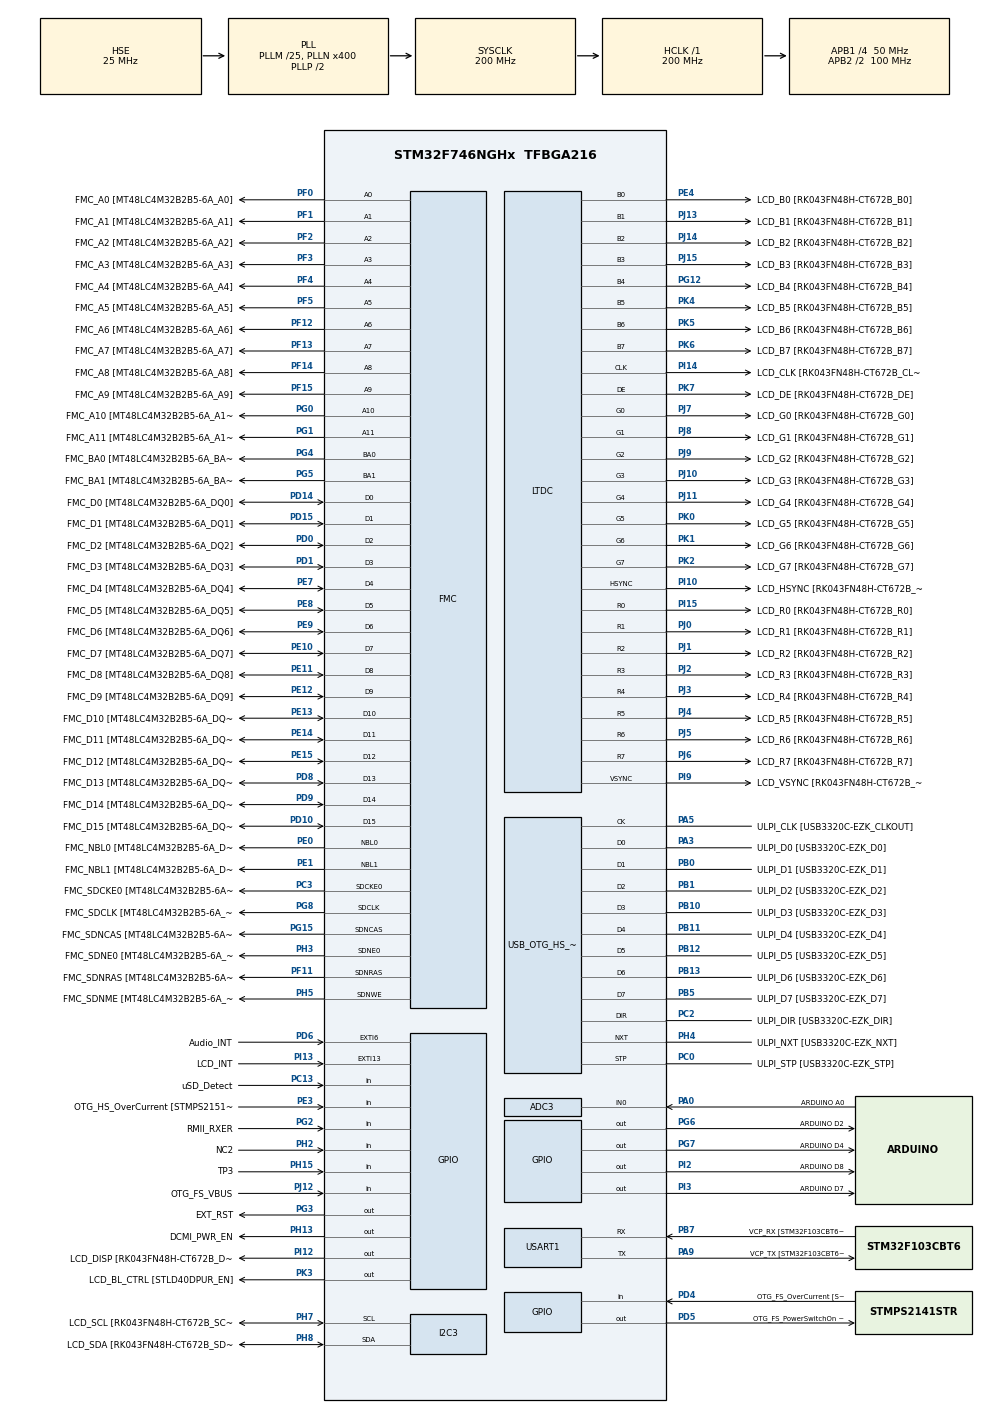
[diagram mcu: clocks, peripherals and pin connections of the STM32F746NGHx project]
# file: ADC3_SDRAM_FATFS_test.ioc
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ADC3.Channel-0\#ChannelRegularConversion=ADC_CHANNEL_0
ADC3.ClockPrescaler=ADC_CLOCK_SYNC_PCLK_DIV4
ADC3.ContinuousConvMode=DISABLE
ADC3.DMAContinuousRequests=DISABLE
ADC3.DataAlign=ADC_DATAALIGN_RIGHT
ADC3.DiscontinuousConvMode=DISABLE
ADC3.EOCSelection=ADC_EOC_SINGLE_CONV
ADC3.EnableAnalogWatchDog=false
ADC3.ExternalTrigConv=ADC_EXTERNALTRIGCONV_T2_TRGO
ADC3.ExternalTrigConvEdge=ADC_EXTERNALTRIGCONVEDGE_RISING
ADC3.InjNumberOfConversion=0
ADC3.NbrOfConversion=1
ADC3.NbrOfConversionFlag=1
ADC3.Rank-0\#ChannelRegularConversion=1
ADC3.Resolution=ADC_RESOLUTION_12B
ADC3.SamplingTime-0\#ChannelRegularConversion=ADC_SAMPLETIME_3CYCLES
ADC3.ScanConvMode=DISABLE
CORTEX_M7.ART_ACCLERATOR_ENABLE=1
CORTEX_M7.CPU_DCache=Enabled
CORTEX_M7.CPU_ICache=Enabled
CORTEX_M7.PREFETCH_ENABLE=1
Dma.ADC3.2.Direction=DMA_PERIPH_TO_MEMORY
Dma.ADC3.2.FIFOMode=DMA_FIFOMODE_DISABLE
Dma.ADC3.2.Instance=DMA2_Stream0
Dma.ADC3.2.MemDataAlignment=DMA_MDATAALIGN_HALFWORD
Dma.ADC3.2.MemInc=DMA_MINC_ENABLE
Dma.ADC3.2.Mode=DMA_NORMAL
Dma.ADC3.2.PeriphDataAlignment=DMA_PDATAALIGN_HALFWORD
Dma.ADC3.2.PeriphInc=DMA_PINC_DISABLE
Dma.ADC3.2.Priority=DMA_PRIORITY_MEDIUM
Dma.MEMTOMEM.0.Direction=DMA_MEMORY_TO_MEMORY
Dma.MEMTOMEM.0.FIFOMode=DMA_FIFOMODE_ENABLE
Dma.MEMTOMEM.0.FIFOThreshold=DMA_FIFO_THRESHOLD_FULL
Dma.MEMTOMEM.0.Instance=DMA2_Stream2
Dma.MEMTOMEM.0.MemBurst=DMA_MBURST_SINGLE
Dma.MEMTOMEM.0.MemDataAlignment=DMA_MDATAALIGN_BYTE
Dma.MEMTOMEM.0.MemInc=DMA_MINC_ENABLE
Dma.MEMTOMEM.0.Mode=DMA_NORMAL
Dma.MEMTOMEM.0.PeriphBurst=DMA_PBURST_SINGLE
Dma.MEMTOMEM.0.PeriphDataAlignment=DMA_PDATAALIGN_BYTE
Dma.MEMTOMEM.0.PeriphInc=DMA_PINC_ENABLE
Dma.MEMTOMEM.0.Priority=DMA_PRIORITY_LOW
Dma.MEMTOMEM.1.Direction=DMA_MEMORY_TO_MEMORY
Dma.MEMTOMEM.1.FIFOMode=DMA_FIFOMODE_ENABLE
Dma.MEMTOMEM.1.FIFOThreshold=DMA_FIFO_THRESHOLD_FULL
Dma.MEMTOMEM.1.Instance=DMA2_Stream1
Dma.MEMTOMEM.1.MemBurst=DMA_MBURST_SINGLE
Dma.MEMTOMEM.1.MemDataAlignment=DMA_MDATAALIGN_BYTE
Dma.MEMTOMEM.1.MemInc=DMA_MINC_ENABLE
Dma.MEMTOMEM.1.Mode=DMA_NORMAL
Dma.MEMTOMEM.1.PeriphBurst=DMA_PBURST_SINGLE
Dma.MEMTOMEM.1.PeriphDataAlignment=DMA_PDATAALIGN_BYTE
Dma.MEMTOMEM.1.PeriphInc=DMA_PINC_ENABLE
Dma.MEMTOMEM.1.Priority=DMA_PRIORITY_LOW
Dma.Request0=MEMTOMEM
Dma.Request1=MEMTOMEM
Dma.Request2=ADC3
FMC.CASLatency1=FMC_SDRAM_CAS_LATENCY_2
FMC.ExitSelfRefreshDelay1=7
FMC.LoadToActiveDelay1=2
FMC.RCDDelay1=2
FMC.RPDelay1=2
FMC.RPDelay2=2
FMC.ReadBurst1=FMC_SDRAM_RBURST_ENABLE
FMC.ReadBurst2=FMC_SDRAM_RBURST_ENABLE
FMC.RowCycleDelay1=6
FMC.RowCycleDelay2=6
FMC.SDClockPeriod1=FMC_SDRAM_CLOCK_PERIOD_2
FMC.SDClockPeriod2=FMC_SDRAM_CLOCK_PERIOD_2
FMC.SelfRefreshTime1=4
FMC.WriteRecoveryTime1=2
FREERTOS.Tasks01=defaultTask,0,128,StartDefaultTask,Default,NULL
I2C3.OwnAddress=112
I2C3.Timing=0x00C0EAFF
LTDC.ActiveH=272
LTDC.ActiveW=480
LTDC.Alpha_L0=255
LTDC.BlendingFactor1_L0=LTDC_BLENDING_FACTOR1_CA
LTDC.BlendingFactor2_L0=LTDC_BLENDING_FACTOR2_CA
LTDC.HBP=13
LTDC.HFP=32
LTDC.HSync=41
LTDC.Layers=0
LTDC.PCPolarity=LTDC_PCPOLARITY_IPC
LTDC.VBP=2
LTDC.VFP=2
LTDC.VSync=10
LTDC.WindowX1_L0=480
LTDC.WindowY1_L0=272
Mcu.Family=STM32F7
Mcu.Name=STM32F746NGHx
Mcu.Package=TFBGA216
NVIC.DMA2_Stream0_IRQn=true\:5\:0\:false\:false\:true\:true\:false
NVIC.OTG_HS_IRQn=true\:5\:0\:false\:false\:true\:true\:false
NVIC.PriorityGroup=NVIC_PRIORITYGROUP_4
NVIC.TIM1_UP_TIM10_IRQn=true\:0\:0\:false\:false\:true\:false\:false
NVIC.TimeBase=TIM1_UP_TIM10_IRQn
NVIC.TimeBaseIP=TIM1
PA0/WKUP.GPIO_Label=ARDUINO A0
PA0/WKUP.GPIO_Mode=GPIO_MODE_ANALOG
PA0/WKUP.GPIO_PuPd=GPIO_NOPULL
PA0/WKUP.Signal=ADCx_IN0
PA1.GPIO_Label=RMII_REF_CLK [LAN8742A-CZ-TR_REFCLK0]
PA1.Signal=ETH_REF_CLK
PA10.GPIO_Label=OTG_FS_ID
PA10.Signal=USB_OTG_FS_ID
PA11.GPIO_Label=OTG_FS_N
PA11.Signal=USB_OTG_FS_DM
PA12.GPIO_Label=OTG_FS_P
PA12.Signal=USB_OTG_FS_DP
PA13.GPIO_Label=SWDIO
PA13.Mode=Serial_Wire
PA13.Signal=SYS_JTMS-SWDIO
PA14.GPIO_Label=SWCLK
PA14.Mode=Serial_Wire
PA14.Signal=SYS_JTCK-SWCLK
PA2.GPIO_Label=RMII_MDIO [LAN8742A-CZ-TR_MDIO]
PA2.Signal=ETH_MDIO
PA3.GPIO_Label=ULPI_D0 [USB3320C-EZK_D0]
PA3.Mode=Host_HS
PA3.Signal=USB_OTG_HS_ULPI_D0
PA4.GPIO_Label=DCMI_HSYNC
PA4.Signal=DCMI_HSYNC
PA5.GPIO_Label=ULPI_CLK [USB3320C-EZK_CLKOUT]
PA5.Mode=Host_HS
PA5.Signal=USB_OTG_HS_ULPI_CK
PA6.Signal=DCMI_PIXCLK
PA7.GPIO_Label=RMII_CRS_DV [LAN8742A-CZ-TR_CRS_DV]
PA7.Signal=ETH_CRS_DV
PA8.GPIO_Label=ARDUINO PWM/D5
PA8.GPIO_ModeDefaultPP=GPIO_MODE_AF_PP
PA8.GPIO_PuPd=GPIO_NOPULL
PA8.GPIO_Speed=GPIO_SPEED_FREQ_LOW
PA8.Signal=S_TIM1_CH1
PA9.GPIO_Label=VCP_TX [STM32F103CBT6_PA3]
PA9.GPIO_Mode=GPIO_MODE_AF_PP
PA9.GPIO_PuPd=GPIO_NOPULL
PA9.GPIO_Speed=GPIO_SPEED_FREQ_LOW
PA9.Mode=Asynchronous
PA9.Signal=USART1_TX
PB0.GPIO_Label=ULPI_D1 [USB3320C-EZK_D1]
PB0.Mode=Host_HS
PB0.Signal=USB_OTG_HS_ULPI_D1
PB1.GPIO_Label=ULPI_D2 [USB3320C-EZK_D2]
PB1.Mode=Host_HS
PB1.Signal=USB_OTG_HS_ULPI_D2
PB10.GPIO_Label=ULPI_D3 [USB3320C-EZK_D3]
PB10.Mode=Host_HS
PB10.Signal=USB_OTG_HS_ULPI_D3
PB11.GPIO_Label=ULPI_D4 [USB3320C-EZK_D4]
PB11.Mode=Host_HS
PB11.Signal=USB_OTG_HS_ULPI_D4
PB12.GPIO_Label=ULPI_D5 [USB3320C-EZK_D5]
PB12.Mode=Host_HS
PB12.Signal=USB_OTG_HS_ULPI_D5
PB13.GPIO_Label=ULPI_D6 [USB3320C-EZK_D6]
PB13.Mode=Host_HS
PB13.Signal=USB_OTG_HS_ULPI_D6
PB14.GPIO_Label=ARDUINO MISO/D12
PB14.GPIO_Mode=GPIO_MODE_AF_PP
PB14.GPIO_PuPd=GPIO_NOPULL
PB14.GPIO_Speed=GPIO_SPEED_FREQ_LOW
PB14.Signal=SPI2_MISO
PB15.GPIO_Label=ARDUINO MOSI/PWM/D11
PB15.GPIO_Mode=GPIO_MODE_AF_PP
PB15.GPIO_PuPd=GPIO_NOPULL
PB15.GPIO_Speed=GPIO_SPEED_FREQ_LOW
PB15.Signal=SPI2_MOSI
PB2.Signal=QUADSPI_CLK
PB3.GPIO_Label=SWO
PB3.Signal=SYS_JTDO-SWO
PB4.GPIO_Label=ARDUINO PWM/D3
PB4.GPIO_ModeDefaultPP=GPIO_MODE_AF_PP
PB4.GPIO_PuPd=GPIO_NOPULL
PB4.GPIO_Speed=GPIO_SPEED_FREQ_LOW
PB4.Signal=S_TIM3_CH1
PB5.GPIO_Label=ULPI_D7 [USB3320C-EZK_D7]
PB5.Mode=Host_HS
PB5.Signal=USB_OTG_HS_ULPI_D7
PB6.GPIO_Label=QSPI_NCS [N25Q128A13EF840E_S]
PB6.Signal=QUADSPI_BK1_NCS
PB7.GPIO_Label=VCP_RX [STM32F103CBT6_PA2]
PB7.GPIO_Mode=GPIO_MODE_AF_PP
PB7.GPIO_PuPd=GPIO_NOPULL
PB7.GPIO_Speed=GPIO_SPEED_FREQ_LOW
PB7.Mode=Asynchronous
PB7.Signal=USART1_RX
PB8.GPIO_Label=ARDUINO SCL/D15
PB8.GPIO_Mode=GPIO_MODE_AF_OD
PB8.GPIO_PuPd=GPIO_NOPULL
PB8.GPIO_Speed=GPIO_SPEED_FREQ_LOW
PB8.Signal=I2C1_SCL
PB9.GPIO_Label=ARDUINO SDA/D14
PB9.GPIO_Mode=GPIO_MODE_AF_OD
PB9.GPIO_PuPd=GPIO_NOPULL
PB9.GPIO_Speed=GPIO_SPEED_FREQ_LOW
PB9.Signal=I2C1_SDA
PC0.GPIO_Label=ULPI_STP [USB3320C-EZK_STP]
PC0.Mode=Host_HS
PC0.Signal=USB_OTG_HS_ULPI_STP
PC1.GPIO_Label=RMII_MDC [LAN8742A-CZ-TR_MDC]
PC1.Signal=ETH_MDC
PC10.GPIO_Label=SDMMC_D2
PC10.Signal=SDMMC1_D2
PC11.GPIO_Label=SDMMC_D3
PC11.Signal=SDMMC1_D3
PC12.GPIO_Label=SDMMC_CK
PC12.Signal=SDMMC1_CK
PC13.GPIO_Label=uSD_Detect
PC13.Signal=GPIO_Input
PC14/OSC32_IN.GPIO_Label=RCC_OSC32_IN
PC14/OSC32_IN.Mode=LSE-External-Oscillator
PC14/OSC32_IN.Signal=RCC_OSC32_IN
PC15/OSC32_OUT.GPIO_Label=RCC_OSC32_OUT
PC15/OSC32_OUT.Mode=LSE-External-Oscillator
PC15/OSC32_OUT.Signal=RCC_OSC32_OUT
PC2.GPIO_Label=ULPI_DIR [USB3320C-EZK_DIR]
PC2.Mode=Host_HS
PC2.Signal=USB_OTG_HS_ULPI_DIR
PC3.GPIO_Label=FMC_SDCKE0 [MT48LC4M32B2B5-6A_CKE]
PC3.Mode=SdramChipSelect1_1
PC3.Signal=FMC_SDCKE0
PC4.GPIO_Label=RMII_RXD0 [LAN8742A-CZ-TR_RXD0]
PC4.Signal=ETH_RXD0
PC5.GPIO_Label=RMII_RXD1 [LAN8742A-CZ-TR_RXD1]
PC5.Signal=ETH_RXD1
PC6.GPIO_Label=ARDUINO TX/D1
PC6.Signal=USART6_TX
PC7.GPIO_Label=ARDUINO RX/D0
PC7.Signal=USART6_RX
PC8.Signal=SDMMC1_D0
PC9.Signal=SDMMC1_D1
PD0.GPIO_Label=FMC_D2 [MT48LC4M32B2B5-6A_DQ2]
PD0.Signal=FMC_D2_DA2
PD1.GPIO_Label=FMC_D3 [MT48LC4M32B2B5-6A_DQ3]
PD1.Signal=FMC_D3_DA3
PD10.GPIO_Label=FMC_D15 [MT48LC4M32B2B5-6A_DQ15]
PD10.Signal=FMC_D15_DA15
PD11.GPIO_Label=QSPI_D0 [N25Q128A13EF840E_DQ0]
PD11.Signal=QUADSPI_BK1_IO0
PD12.GPIO_Label=QSPI_D1 [N25Q128A13EF840E_DQ1]
PD12.Signal=QUADSPI_BK1_IO1
PD13.GPIO_Label=QSPI_D3 [N25Q128A13EF840E_DQ3]
PD13.Signal=QUADSPI_BK1_IO3
PD14.GPIO_Label=FMC_D0 [MT48LC4M32B2B5-6A_DQ0]
PD14.Signal=FMC_D0_DA0
PD15.GPIO_Label=FMC_D1 [MT48LC4M32B2B5-6A_DQ1]
PD15.Signal=FMC_D1_DA1
PD2.GPIO_Label=SDMMC_D0
PD2.Signal=SDMMC1_CMD
PD3.GPIO_Label=DCMI_D5
PD3.Signal=DCMI_D5
PD4.GPIO_Label=OTG_FS_OverCurrent [STMPS2141STR_Fault]
PD4.Signal=GPIO_Input
PD5.GPIO_Label=OTG_FS_PowerSwitchOn [STMPS2141STR_EN]
PD5.PinState=GPIO_PIN_SET
PD5.Signal=GPIO_Output
PD6.GPIO_Label=Audio_INT
PD6.GPIO_ModeDefaultEXTI=GPIO_MODE_EVT_RISING
PD6.Signal=GPXTI6
PD7.GPIO_Label=SPDIF_RX0 [74LVC1G04SE_4]
PD7.Signal=SPDIFRX_IN0
PD8.GPIO_Label=FMC_D13 [MT48LC4M32B2B5-6A_DQ13]
PD8.Signal=FMC_D13_DA13
PD9.GPIO_Label=FMC_D14 [MT48LC4M32B2B5-6A_DQ14]
PD9.Signal=FMC_D14_DA14
PE0.GPIO_Label=FMC_NBL0 [MT48LC4M32B2B5-6A_DQM0]
PE0.Signal=FMC_NBL0
PE1.GPIO_Label=FMC_NBL1 [MT48LC4M32B2B5-6A_DQM1]
PE1.Signal=FMC_NBL1
PE10.GPIO_Label=FMC_D7 [MT48LC4M32B2B5-6A_DQ7]
PE10.Signal=FMC_D7_DA7
PE11.GPIO_Label=FMC_D8 [MT48LC4M32B2B5-6A_DQ8]
PE11.Signal=FMC_D8_DA8
PE12.GPIO_Label=FMC_D9 [MT48LC4M32B2B5-6A_DQ9]
PE12.Signal=FMC_D9_DA9
PE13.GPIO_Label=FMC_D10 [MT48LC4M32B2B5-6A_DQ10]
PE13.Signal=FMC_D10_DA10
PE14.GPIO_Label=FMC_D11 [MT48LC4M32B2B5-6A_DQ11]
PE14.Signal=FMC_D11_DA11
PE15.GPIO_Label=FMC_D12 [MT48LC4M32B2B5-6A_DQ12]
PE15.Signal=FMC_D12_DA12
PE2.GPIO_Label=QSPI_D2 [N25Q128A13EF840E_DQ2]
PE2.Signal=QUADSPI_BK1_IO2
PE3.GPIO_Label=OTG_HS_OverCurrent [STMPS2151STR_FAULT]
PE3.Signal=GPIO_Input
PE4.GPIO_Label=LCD_B0 [RK043FN48H-CT672B_B0]
PE4.Mode=RGB888
PE4.Signal=LTDC_B0
PE5.GPIO_Label=DCMI_D6
PE5.Signal=DCMI_D6
PE6.GPIO_Label=DCMI_D7
PE6.Signal=DCMI_D7
PE7.GPIO_Label=FMC_D4 [MT48LC4M32B2B5-6A_DQ4]
PE7.Signal=FMC_D4_DA4
PE8.GPIO_Label=FMC_D5 [MT48LC4M32B2B5-6A_DQ5]
PE8.Signal=FMC_D5_DA5
PE9.GPIO_Label=FMC_D6 [MT48LC4M32B2B5-6A_DQ6]
PE9.Signal=FMC_D6_DA6
PF0.GPIO_Label=FMC_A0 [MT48LC4M32B2B5-6A_A0]
PF0.Signal=FMC_A0
PF1.GPIO_Label=FMC_A1 [MT48LC4M32B2B5-6A_A1]
PF1.Signal=FMC_A1
PF10.GPIO_Label=ARDUINO A1
PF10.GPIO_Mode=GPIO_MODE_ANALOG
PF10.GPIO_PuPd=GPIO_NOPULL
PF10.Signal=ADC3_IN8
PF11.GPIO_Label=FMC_SDNRAS [MT48LC4M32B2B5-6A_RAS]
PF11.Signal=FMC_SDNRAS
PF12.GPIO_Label=FMC_A6 [MT48LC4M32B2B5-6A_A6]
PF12.Signal=FMC_A6
PF13.GPIO_Label=FMC_A7 [MT48LC4M32B2B5-6A_A7]
PF13.Signal=FMC_A7
PF14.GPIO_Label=FMC_A8 [MT48LC4M32B2B5-6A_A8]
PF14.Signal=FMC_A8
PF15.GPIO_Label=FMC_A9 [MT48LC4M32B2B5-6A_A9]
PF15.Signal=FMC_A9
PF2.GPIO_Label=FMC_A2 [MT48LC4M32B2B5-6A_A2]
PF2.Signal=FMC_A2
PF3.GPIO_Label=FMC_A3 [MT48LC4M32B2B5-6A_A3]
PF3.Signal=FMC_A3
PF4.GPIO_Label=FMC_A4 [MT48LC4M32B2B5-6A_A4]
PF4.Signal=FMC_A4
PF5.GPIO_Label=FMC_A5 [MT48LC4M32B2B5-6A_A5]
PF5.Signal=FMC_A5
PF6.GPIO_Label=ARDUINO A5
PF6.GPIO_Mode=GPIO_MODE_ANALOG
PF6.GPIO_PuPd=GPIO_NOPULL
PF6.Signal=ADC3_IN4
PF7.GPIO_Label=ARDUINO A4
PF7.GPIO_Mode=GPIO_MODE_ANALOG
PF7.GPIO_PuPd=GPIO_NOPULL
PF7.Signal=ADC3_IN5
PF8.GPIO_Label=ARDUINO A3
PF8.GPIO_Mode=GPIO_MODE_ANALOG
PF8.GPIO_PuPd=GPIO_NOPULL
PF8.Signal=ADC3_IN6
PF9.GPIO_Label=ARDUINO A2
PF9.GPIO_Mode=GPIO_MODE_ANALOG
PF9.GPIO_PuPd=GPIO_NOPULL
PF9.Signal=ADC3_IN7
PG0.GPIO_Label=FMC_A10 [MT48LC4M32B2B5-6A_A10]
PG0.Signal=FMC_A10
PG1.GPIO_Label=FMC_A11 [MT48LC4M32B2B5-6A_A11]
PG1.Signal=FMC_A11
PG10.GPIO_Label=SAI2_SDB [WM8994ECS/R_ADCDAT1]
PG10.Signal=SAI2_SD_B
PG11.GPIO_Label=RMII_TX_EN [LAN8742A-CZ-TR_TXEN]
PG11.Signal=ETH_TX_EN
PG12.GPIO_Label=LCD_B4 [RK043FN48H-CT672B_B4]
PG12.Mode=RGB888
PG12.Signal=LTDC_B4
PG13.GPIO_Label=RMII_TXD0 [LAN8742A-CZ-TR_TXD0]
PG13.Signal=ETH_TXD0
PG14.GPIO_Label=RMII_TXD1 [LAN8742A-CZ-TR_TXD1]
PG14.Signal=ETH_TXD1
PG15.GPIO_Label=FMC_SDNCAS [MT48LC4M32B2B5-6A_CAS]
PG15.Signal=FMC_SDNCAS
PG2.GPIO_Label=RMII_RXER
PG2.Signal=GPIO_Input
PG3.GPIO_Label=EXT_RST
PG3.Signal=GPIO_Output
PG4.GPIO_Label=FMC_BA0 [MT48LC4M32B2B5-6A_BA0]
PG4.Signal=FMC_A14_BA0
PG5.GPIO_Label=FMC_BA1 [MT48LC4M32B2B5-6A_BA1]
PG5.Signal=FMC_A15_BA1
PG6.GPIO_Label=ARDUINO D2
PG6.Signal=GPIO_Output
PG7.GPIO_Label=ARDUINO D4
PG7.Signal=GPIO_Output
PG8.GPIO_Label=FMC_SDCLK [MT48LC4M32B2B5-6A_CLK]
PG8.Signal=FMC_SDCLK
PG9.GPIO_Label=DCMI_VSYNC
PG9.Signal=DCMI_VSYNC
PH0/OSC_IN.GPIO_Label=OSC_25M [NZ2520SB-25.00M_OUT]
PH0/OSC_IN.Mode=HSE-External-Oscillator
PH0/OSC_IN.Signal=RCC_OSC_IN
PH1/OSC_OUT.Mode=HSE-External-Oscillator
PH1/OSC_OUT.Signal=RCC_OSC_OUT
PH10.GPIO_Label=DCMI_D1
PH10.Signal=DCMI_D1
PH11.GPIO_Label=DCMI_D2
PH11.Signal=DCMI_D2
PH12.GPIO_Label=DCMI_D3
PH12.Signal=DCMI_D3
PH13.GPIO_Label=DCMI_PWR_EN
PH13.Signal=GPIO_Output
PH14.GPIO_Label=DCMI_D4
PH14.Signal=DCMI_D4
PH15.GPIO_Label=TP3
PH15.Signal=GPIO_Input
PH2.GPIO_Label=NC2
PH2.Signal=GPIO_Input
PH3.GPIO_Label=FMC_SDNE0 [MT48LC4M32B2B5-6A_CS]
PH3.Mode=SdramChipSelect1_1
PH3.Signal=FMC_SDNE0
PH4.GPIO_Label=ULPI_NXT [USB3320C-EZK_NXT]
PH4.Mode=Host_HS
PH4.Signal=USB_OTG_HS_ULPI_NXT
PH5.GPIO_Label=FMC_SDNME [MT48LC4M32B2B5-6A_WE]
PH5.Signal=FMC_SDNWE
PH6.GPIO_Label=ARDUINO PWM/D6
PH6.Signal=S_TIM12_CH1
PH7.GPIO_Label=LCD_SCL [RK043FN48H-CT672B_SCL]
PH7.Mode=I2C
PH7.Signal=I2C3_SCL
PH8.GPIO_Label=LCD_SDA [RK043FN48H-CT672B_SDA]
PH8.Mode=I2C
PH8.Signal=I2C3_SDA
PH9.GPIO_Label=DCMI_D0
PH9.Signal=DCMI_D0
PI0.GPIO_Label=ARDUINO PWM/CS/D10
PI0.GPIO_ModeDefaultPP=GPIO_MODE_AF_PP
PI0.GPIO_PuPd=GPIO_NOPULL
PI0.GPIO_Speed=GPIO_SPEED_FREQ_LOW
PI0.Signal=S_TIM5_CH4
PI1.GPIO_Label=ARDUINO SCK/D13
PI1.GPIO_Mode=GPIO_MODE_AF_PP
PI1.GPIO_PuPd=GPIO_NOPULL
PI1.GPIO_Speed=GPIO_SPEED_FREQ_LOW
PI1.Signal=SPI2_SCK
PI10.GPIO_Label=LCD_HSYNC [RK043FN48H-CT672B_HSYNC]
PI10.Mode=RGB888
PI10.Signal=LTDC_HSYNC
PI11.Mode=SYS_WakeUp5
PI11.Signal=SYS_WKUP6
PI12.GPIO_Label=LCD_DISP [RK043FN48H-CT672B_DISP] 
PI12.Signal=GPIO_Output
PI13.GPIO_Label=LCD_INT
PI13.GPIO_ModeDefaultEXTI=GPIO_MODE_EVT_RISING
PI13.Signal=GPXTI13
PI14.GPIO_Label=LCD_CLK [RK043FN48H-CT672B_CLK]
PI14.Mode=RGB888
PI14.Signal=LTDC_CLK
PI15.GPIO_Label=LCD_R0 [RK043FN48H-CT672B_R0]
PI15.Mode=RGB888
PI15.Signal=LTDC_R0
PI2.GPIO_Label=ARDUINO D8
PI2.Signal=GPIO_Output
PI3.GPIO_Label=ARDUINO D7
PI3.Signal=GPIO_Output
PI4.GPIO_Label=SAI2_MCLKA [WM8994ECS/R_MCLK1]
PI4.Signal=SAI2_MCLK_A
PI5.GPIO_Label=SAI2_SCKA [WM8994ECS/R_BCLK1]
PI5.Signal=SAI2_SCK_A
PI6.GPIO_Label=SAI2_SDA [WM8994ECS/R_DACDAT1]
PI6.Signal=SAI2_SD_A
PI7.GPIO_Label=SAI2_FSA [WM8994ECS/R_LRCLK1]
PI7.Signal=SAI2_FS_A
PI8.GPIO_Label=NC1 [TP2]
PI8.Signal=RTC_TS
PI9.GPIO_Label=LCD_VSYNC [RK043FN48H-CT672B_VSYNC]
PI9.Mode=RGB888
PI9.Signal=LTDC_VSYNC
PJ0.GPIO_Label=LCD_R1 [RK043FN48H-CT672B_R1]
PJ0.Mode=RGB888
PJ0.Signal=LTDC_R1
PJ1.GPIO_Label=LCD_R2 [RK043FN48H-CT672B_R2]
PJ1.Mode=RGB888
PJ1.Signal=LTDC_R2
PJ10.GPIO_Label=LCD_G3 [RK043FN48H-CT672B_G3]
PJ10.Mode=RGB888
PJ10.Signal=LTDC_G3
PJ11.GPIO_Label=LCD_G4 [RK043FN48H-CT672B_G4]
PJ11.Mode=RGB888
PJ11.Signal=LTDC_G4
PJ12.GPIO_Label=OTG_FS_VBUS
PJ12.Signal=GPIO_Input
PJ13.GPIO_Label=LCD_B1 [RK043FN48H-CT672B_B1]
PJ13.Mode=RGB888
PJ13.Signal=LTDC_B1
PJ14.GPIO_Label=LCD_B2 [RK043FN48H-CT672B_B2]
PJ14.Mode=RGB888
PJ14.Signal=LTDC_B2
PJ15.GPIO_Label=LCD_B3 [RK043FN48H-CT672B_B3]
PJ15.Mode=RGB888
PJ15.Signal=LTDC_B3
PJ2.GPIO_Label=LCD_R3 [RK043FN48H-CT672B_R3]
PJ2.Mode=RGB888
PJ2.Signal=LTDC_R3
PJ3.GPIO_Label=LCD_R4 [RK043FN48H-CT672B_R4]
PJ3.Mode=RGB888
PJ3.Signal=LTDC_R4
PJ4.GPIO_Label=LCD_R5 [RK043FN48H-CT672B_R5]
PJ4.Mode=RGB888
PJ4.Signal=LTDC_R5
PJ5.GPIO_Label=LCD_R6 [RK043FN48H-CT672B_R6]
PJ5.Mode=RGB888
PJ5.Signal=LTDC_R6
PJ6.GPIO_Label=LCD_R7 [RK043FN48H-CT672B_R7]
PJ6.Mode=RGB888
PJ6.Signal=LTDC_R7
PJ7.GPIO_Label=LCD_G0 [RK043FN48H-CT672B_G0]
PJ7.Mode=RGB888
PJ7.Signal=LTDC_G0
PJ8.GPIO_Label=LCD_G1 [RK043FN48H-CT672B_G1]
PJ8.Mode=RGB888
PJ8.Signal=LTDC_G1
PJ9.GPIO_Label=LCD_G2 [RK043FN48H-CT672B_G2]
PJ9.Mode=RGB888
PJ9.Signal=LTDC_G2
PK0.GPIO_Label=LCD_G5 [RK043FN48H-CT672B_G5]
PK0.Mode=RGB888
PK0.Signal=LTDC_G5
PK1.GPIO_Label=LCD_G6 [RK043FN48H-CT672B_G6]
PK1.Mode=RGB888
PK1.Signal=LTDC_G6
PK2.GPIO_Label=LCD_G7 [RK043FN48H-CT672B_G7]
PK2.Mode=RGB888
PK2.Signal=LTDC_G7
PK3.GPIO_Label=LCD_BL_CTRL [STLD40DPUR_EN]
PK3.Signal=GPIO_Output
PK4.GPIO_Label=LCD_B5 [RK043FN48H-CT672B_B5]
PK4.Mode=RGB888
PK4.Signal=LTDC_B5
PK5.GPIO_Label=LCD_B6 [RK043FN48H-CT672B_B6]
PK5.Mode=RGB888
PK5.Signal=LTDC_B6
PK6.GPIO_Label=LCD_B7 [RK043FN48H-CT672B_B7]
PK6.Mode=RGB888
PK6.Signal=LTDC_B7
PK7.GPIO_Label=LCD_DE [RK043FN48H-CT672B_DE]
PK7.Mode=RGB888
PK7.Signal=LTDC_DE
ProjectManager.HeapSize=0x200
ProjectManager.StackSize=0x400
ProjectManager.TargetToolchain=TrueSTUDIO
RCC.AHBFreq_Value=200000000
RCC.APB1CLKDivider=RCC_HCLK_DIV4
RCC.APB1Freq_Value=50000000
RCC.APB1TimFreq_Value=100000000
RCC.APB2CLKDivider=RCC_HCLK_DIV2
RCC.APB2Freq_Value=100000000
RCC.APB2TimFreq_Value=200000000
RCC.CortexFreq_Value=200000000
RCC.HCLKFreq_Value=200000000
RCC.HSE_VALUE=25000000
RCC.HSI_VALUE=16000000
RCC.PLLI2SN=100
RCC.PLLM=25
RCC.PLLN=400
RCC.PLLQ=9
RCC.PLLSAIN=190
RCC.PLLSAIR=5
RCC.PLLSAIRDiv=RCC_PLLSAIDIVR_4
RCC.PLLSourceVirtual=RCC_PLLSOURCE_HSE
RCC.SYSCLKFreq_VALUE=200000000
RCC.SYSCLKSource=RCC_SYSCLKSOURCE_PLLCLK
RCC.USBFreq_Value=44444444.44444445
RCC.VCOOutputFreq_Value=400000000
SH.ADCx_IN0.0=ADC3_IN0,IN0
SH.FMC_A0.0=FMC_A0,12b-sda1
SH.FMC_A1.0=FMC_A1,12b-sda1
SH.FMC_A10.0=FMC_A10,12b-sda1
SH.FMC_A11.0=FMC_A11,12b-sda1
SH.FMC_A14_BA0.0=FMC_BA0,FourSdramBanks1
SH.FMC_A15_BA1.0=FMC_BA1,FourSdramBanks1
SH.FMC_A2.0=FMC_A2,12b-sda1
SH.FMC_A3.0=FMC_A3,12b-sda1
SH.FMC_A4.0=FMC_A4,12b-sda1
SH.FMC_A5.0=FMC_A5,12b-sda1
SH.FMC_A6.0=FMC_A6,12b-sda1
SH.FMC_A7.0=FMC_A7,12b-sda1
SH.FMC_A8.0=FMC_A8,12b-sda1
SH.FMC_A9.0=FMC_A9,12b-sda1
SH.FMC_D0_DA0.0=FMC_D0,sd-16b-d1
SH.FMC_D10_DA10.0=FMC_D10,sd-16b-d1
SH.FMC_D11_DA11.0=FMC_D11,sd-16b-d1
SH.FMC_D12_DA12.0=FMC_D12,sd-16b-d1
SH.FMC_D13_DA13.0=FMC_D13,sd-16b-d1
SH.FMC_D14_DA14.0=FMC_D14,sd-16b-d1
SH.FMC_D15_DA15.0=FMC_D15,sd-16b-d1
SH.FMC_D1_DA1.0=FMC_D1,sd-16b-d1
SH.FMC_D2_DA2.0=FMC_D2,sd-16b-d1
SH.FMC_D3_DA3.0=FMC_D3,sd-16b-d1
SH.FMC_D4_DA4.0=FMC_D4,sd-16b-d1
SH.FMC_D5_DA5.0=FMC_D5,sd-16b-d1
SH.FMC_D6_DA6.0=FMC_D6,sd-16b-d1
SH.FMC_D7_DA7.0=FMC_D7,sd-16b-d1
SH.FMC_D8_DA8.0=FMC_D8,sd-16b-d1
SH.FMC_D9_DA9.0=FMC_D9,sd-16b-d1
SH.FMC_NBL0.0=FMC_NBL0,Sd2ByteEnable1
SH.FMC_NBL1.0=FMC_NBL1,Sd2ByteEnable1
SH.FMC_SDCLK.0=FMC_SDCLK,12b-sda1
SH.FMC_SDNCAS.0=FMC_SDNCAS,12b-sda1
SH.FMC_SDNRAS.0=FMC_SDNRAS,12b-sda1
SH.FMC_SDNWE.0=FMC_SDNWE,12b-sda1
SH.S_TIM12_CH1.0=TIM12_CH1
SH.S_TIM1_CH1.0=TIM1_CH1
SH.S_TIM3_CH1.0=TIM3_CH1
SH.S_TIM5_CH4.0=TIM5_CH4
TIM2.Period=100
TIM2.Prescaler=0
TIM2.TIM_MasterOutputTrigger=TIM_TRGO_UPDATE
TIM3.Period=100
TIM3.TIM_MasterOutputTrigger=TIM_TRGO_UPDATE
USART1.VirtualMode-Asynchronous=VM_ASYNC
USART1.WordLength=WORDLENGTH_8B
USB_HOST.USBH_HandleTypeDef-MSC_HS=hUsbHostHS
USB_HOST.VirtualModeHS=Msc
USB_OTG_HS.VirtualMode-Host_HS=Host_HS
VP_CRC_VS_CRC.Mode=CRC_Activate
VP_DMA2D_VS_DMA2D.Mode=DMA2D_Activate
VP_FATFS_VS_FMC_SDRAM.Mode=FMC_SDRAM
VP_FREERTOS_VS_ENABLE.Mode=Enabled
VP_SYS_VS_tim1.Mode=TIM1
VP_TIM2_VS_ClockSourceINT.Mode=Internal
VP_TIM3_VS_ClockSourceINT.Mode=Internal
VP_USB_HOST_VS_USB_HOST_MSC_HS.Mode=MSC_HS
VP_WWDG_VS_WWDG.Mode=WWDG_Activate
WWDG.Prescaler=WWDG_PRESCALER_8
board=32F746GDISCOVERY

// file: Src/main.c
/**
  ******************************************************************************
  * @file           : main.c
  * @brief          : Main program body
  ******************************************************************************
  * This notice applies to any and all portions of this file
  * that are not between comment pairs USER CODE BEGIN and
  * USER CODE END. Other portions of this file, whether
  * inserted by the user or by software development tools
  * are owned by their respective copyright owners.
  *
  * Copyright (c) 2018 STMicroelectronics International N.V.
  * All rights reserved.
  *
  * Redistribution and use in source and binary forms, with or without
  * modification, are permitted, provided that the following conditions are met:
  *
  * 1. Redistribution of source code must retain the above copyright notice,
  *    this list of conditions and the following disclaimer.
  * 2. Redistributions in binary form must reproduce the above copyright notice,
  *    this list of conditions and the following disclaimer in the documentation
  *    and/or other materials provided with the distribution.
  * 3. Neither the name of STMicroelectronics nor the names of other
  *    contributors to this software may be used to endorse or promote products
  *    derived from this software without specific written permission.
  * 4. This software, including modifications and/or derivative works of this
  *    software, must execute solely and exclusively on microcontroller or
  *    microprocessor devices manufactured by or for STMicroelectronics.
  * 5. Redistribution and use of this software other than as permitted under
  *    this license is void and will automatically terminate your rights under
  *    this license.
  *
  * THIS SOFTWARE IS PROVIDED BY STMICROELECTRONICS AND CONTRIBUTORS "AS IS"
  * AND ANY EXPRESS, IMPLIED OR STATUTORY WARRANTIES, INCLUDING, BUT NOT
  * LIMITED TO, THE IMPLIED WARRANTIES OF MERCHANTABILITY, FITNESS FOR A
  * PARTICULAR PURPOSE AND NON-INFRINGEMENT OF THIRD PARTY INTELLECTUAL PROPERTY
  * RIGHTS ARE DISCLAIMED TO THE FULLEST EXTENT PERMITTED BY LAW. IN NO EVENT
  * SHALL STMICROELECTRONICS OR CONTRIBUTORS BE LIABLE FOR ANY DIRECT, INDIRECT,
  * INCIDENTAL, SPECIAL, EXEMPLARY, OR CONSEQUENTIAL DAMAGES (INCLUDING, BUT NOT
  * LIMITED TO, PROCUREMENT OF SUBSTITUTE GOODS OR SERVICES; LOSS OF USE, DATA,
  * OR PROFITS; OR BUSINESS INTERRUPTION) HOWEVER CAUSED AND ON ANY THEORY OF
  * LIABILITY, WHETHER IN CONTRACT, STRICT LIABILITY, OR TORT (INCLUDING
  * NEGLIGENCE OR OTHERWISE) ARISING IN ANY WAY OUT OF THE USE OF THIS SOFTWARE,
  * EVEN IF ADVISED OF THE POSSIBILITY OF SUCH DAMAGE.
  *
  ******************************************************************************
  */
#include "main.h"
#include "stm32f7xx_hal.h"
#include "cmsis_os.h"
#include "fatfs.h"
#include "usb_host.h"

/* USER CODE BEGIN Includes */

// LoadCell_STM32_RAM v2 main
// (C) Tapio Valli 2018-02-20

#include "stm32746g_discovery.h"
#include "stm32746g_discovery_lcd.h"

#include <stdio.h>
#include <errno.h>
#include <stdint.h>
#include <stdio.h>
#include <stdlib.h>
#include <string.h>
#include <assert.h>
#include <ctype.h>

#include "MyString.h"

#include "ff.h"         /* Declarations of sector size */
#include "diskio.h"     /* Declarations of disk functions */

/* USER CODE END Includes */

ADC_HandleTypeDef hadc3;
DMA_HandleTypeDef hdma_adc3;

CRC_HandleTypeDef hcrc;

DMA2D_HandleTypeDef hdma2d;

I2C_HandleTypeDef hi2c3;

LTDC_HandleTypeDef hltdc;

TIM_HandleTypeDef htim2;
TIM_HandleTypeDef htim3;

UART_HandleTypeDef huart1;

WWDG_HandleTypeDef hwwdg;

DMA_HandleTypeDef hdma_memtomem_dma2_stream2;
DMA_HandleTypeDef hdma_memtomem_dma2_stream1;
SDRAM_HandleTypeDef hsdram1;

osThreadId defaultTaskHandle;

/* USER CODE BEGIN PV */
/* Private variables ---------------------------------------------------------*/

FATFS SDRAMFatFs;
FIL MyFile;
char SDRAMPath[4]; /* SDRAM card logical drive path */
uint8_t workBuffer[_MAX_SS];

const Diskio_drvTypeDef SDRAMDISK_Driver;

/* USER CODE END PV */

void SystemClock_Config(void);
static void MX_GPIO_Init(void);
static void MX_DMA_Init(void);
static void MX_FMC_Init(void);
static void MX_ADC3_Init(void);
static void MX_USART1_UART_Init(void);
static void MX_LTDC_Init(void);
static void MX_I2C3_Init(void);
static void MX_DMA2D_Init(void);
static void MX_CRC_Init(void);
static void MX_WWDG_Init(void);
static void MX_TIM2_Init(void);
static void MX_TIM3_Init(void);
void StartDefaultTask(void const * argument);

/* USER CODE BEGIN PFP */
/* Private function prototypes -----------------------------------------------*/

extern int __io_putchar(int ch);
extern int _write(int file, char *ptr, int len);

extern void BSP_SDRAM_Initialization_Sequence(SDRAM_HandleTypeDef *hsdram,
		FMC_SDRAM_CommandTypeDef *Command);

extern void initArray(Array *a, size_t initialSize);
extern void insertArray(Array *a, uint32_t newsize);
extern void freeArray(Array *a);

extern char * myPrintf(float f);
extern size_t string_parser(char *input, char ***word_array);
extern char * string_parse(char * parse_string, uint8_t idx);
extern void PlotData(uint32_t XCoordinate, uint32_t YCoordinate);
extern void InitScreen(uint32_t BackGroundColor, uint32_t ForeGroundColor);
extern void LCDWrite(uint32_t Line, char Str[]);
extern void CountDown(uint32_t millisecs);
extern FRESULT scan_files(char* path);
extern void SamplePoints(Array *Data, uint32_t NoOfPoints, uint32_t Period_us);
extern void AvgAndPlotPoints(Array *Data, uint32_t NoOfPoints, uint32_t AvgSize);
extern void WriteData2FS(const Diskio_drvTypeDef SDRAMDISK_Driver,
		FATFS SDRAMFatFs, char SDRAMPath[4], FIL MyFile, Array *Data,
		uint32_t NoOfPoints, uint32_t MeasNo);
extern void DirList(void);

extern int test_diskio(BYTE pdrv, /* Physical drive number to be checked (all data on the drive will be lost) */
UINT ncyc, /* Number of test cycles */
DWORD* buff, /* Pointer to the working buffer */
UINT sz_buff /* Size of the working buffer in unit of byte */
);

/* USER CODE END PFP */

int main(void)
{
	/* USER CODE BEGIN 1 */

	FRESULT res; /* FatFs function common result code */
	uint32_t byteswritten, bytesread; /* File write/read counts */
	uint8_t wtext[] = "This is STM32 working with FatFs"; /* File write buffer */
	uint8_t rtext[100]; /* File read buffer */

	/* USER CODE END 1 */

	/* Enable I-Cache-------------------------------------------------------------*/
	SCB_EnableICache();

	/* Enable D-Cache-------------------------------------------------------------*/
	SCB_EnableDCache();

	/* MCU Configuration----------------------------------------------------------*/

	/* Reset of all peripherals, Initializes the Flash interface and the Systick. */
	HAL_Init();

	/* Configure the system clock */
	SystemClock_Config();

	/* Initialize all configured peripherals */
	MX_GPIO_Init();
	MX_DMA_Init();
	MX_FMC_Init();
	MX_ADC3_Init();
	MX_USART1_UART_Init();
	MX_LTDC_Init();
	MX_I2C3_Init();
	MX_DMA2D_Init();
	MX_CRC_Init();
	MX_WWDG_Init();
	MX_TIM2_Init();
	MX_TIM3_Init();

	/* USER CODE BEGIN 2 */

	// Start SDRAM
	FMC_SDRAM_CommandTypeDef hsdram1Command;
	BSP_SDRAM_Initialization_Sequence(&hsdram1, &hsdram1Command);

	// Start LCD
	BSP_LCD_Init();
	BSP_LCD_LayerDefaultInit(0, LCD_FB_START_ADDRESS);
	BSP_LCD_SelectLayer(0);
	BSP_LCD_DisplayOn();
	BSP_LCD_Clear(LCD_COLOR_WHITE);
	BSP_LCD_SetBackColor(LCD_COLOR_WHITE);
	BSP_LCD_SetTextColor(LCD_COLOR_BLUE);
	BSP_LCD_DisplayStringAtLine(5, (uint8_t*) "Hello to everyone 1!");
	HAL_Delay(3000);
	BSP_LCD_Clear(LCD_COLOR_BLUE);
	BSP_LCD_SetBackColor(LCD_COLOR_BLUE);
	BSP_LCD_SetTextColor(LCD_COLOR_WHITE);
	BSP_LCD_DisplayStringAtLine(5, (uint8_t*) "Hello to everyone 2!");
	HAL_Delay(3000);
	BSP_LCD_Clear(LCD_COLOR_BLACK);
	BSP_LCD_SetBackColor(LCD_COLOR_BLACK);
	BSP_LCD_SetTextColor(LCD_COLOR_WHITE);

	// Initialize SDRAM FATFS
	printf("Format SDRAM disk ... \r\n");
	if (FATFS_LinkDriver(&SDRAMDISK_Driver, SDRAMPath) == 0) {
		printf("	SDRAM FATFS link Success \r\n");
	}
	// Register the file system object to the FatFs module
	if (f_mount(&SDRAMFatFs, (TCHAR const*) SDRAMPath, 0) != FR_OK) {
		// FatFs Initialization Error
		_Error_Handler(__FILE__, __LINE__);
	} else {
		printf("	SDRAM FATFS mount Success \r\n");
	}
	// Create a FAT file system (format) on the logical drive
	if (f_mkfs((TCHAR const*) SDRAMPath, FM_FAT32, 0, workBuffer,
			sizeof(workBuffer)) != FR_OK) {
		// FatFs Format Error
		_Error_Handler(__FILE__, __LINE__);
	} else {
		printf("Format SDRAM disk done OK \r\n");
	}

	// Unlink the SDRAM disk I/O driver
	FATFS_UnLinkDriver(SDRAMPath);

	int rc;
	DWORD buff[_MAX_SS]; /* Working buffer (4 sector in size) */

	/* Check function/compatibility of the physical drive #0 */
//	rc = test_diskio(0, 3, buff, sizeof buff);
//
//	if (rc) {
//		printf(
//				"Sorry the function/compatibility test failed. (rc=%d)\nFatFs will not work with this disk driver.\n",
//				rc);
//	} else {
//		printf("Congratulations! The disk driver works well.\n");
//	}

	char *cmdPtr;
	char *argPtr;

	char Arg[30];
	char Cmd[30];
	char CmdBuffer[30];

	uint8_t n = 0;
	uint32_t MeasNo = 0;

	uint32_t NoOfPoints = 19200;
	uint32_t AvgSize = 10;
	uint32_t Period_us = 100;
	uint32_t Count_ms = 1000;

	// Clear screen, set it up
	InitScreen(LCD_COLOR_BLACK, LCD_COLOR_WHITE);

	// Initialize data storage
	// https://stackoverflow.com/questions/3536153/c-dynamically-growing-array
	Array Data;
	initArray(&Data, NoOfPoints);  // initially 19200 elements

	// LCDWrite(5, "Ready.");

	Cmd[0] = '\0';
	Arg[0] = '\0';

	while (!((strcmp(Cmd, "quit") == 0) && (n == 0))) {

		// Print Ready and current settings

		printf(
				"Ready. Settings are Points=%lu, Avg=%lu, Period_us=%lu, Count_ms=%lu. "
						"Sampling will take apprx %s secs \r\n", NoOfPoints,
				AvgSize, Period_us, Count_ms,
				myPrintf(NoOfPoints * Period_us / 1000000.0));

		Cmd[0] = '\0';
		Arg[0] = '\0';

		strcpy(CmdBuffer, " ");
		while ((strcmp(CmdBuffer, " ") == 0) || (CmdBuffer[0] == '\0')) {
			String_GetString((uint8_t *) CmdBuffer);
		}

		//printf("\r\n I got %s \r\n", CmdBuffer);

		// Parse and copy arg 0
		cmdPtr = string_parse((char *) CmdBuffer, 0);

		uint8_t i = 0;
		while (*cmdPtr != '\0') {
			Cmd[i] = (char) *cmdPtr;
			i++;
			cmdPtr++;
		}
		Cmd[i] = '\0';

		argPtr = string_parse((char *) CmdBuffer, 1);

		i = 0;
		while ((argPtr != NULL) && (*argPtr != '\0')) {
			Arg[i] = (char) *argPtr;
			i++;
			argPtr++;
		}
		Arg[i] = '\0';

		// Branch based on command

		// Length of the second argument
		n = strlen(Arg);

		// meas: Sample and plot a data set
		if ((strcmp(Cmd, "meas") == 0) && (n == 0)) {

			// Countdown
			CountDown(Count_ms);

			MeasNo++;

			// Sample & plot data one time
			SamplePoints(&Data, NoOfPoints, Period_us);
			AvgAndPlotPoints(&Data, NoOfPoints, AvgSize);

			// Write the unaveraged (full) data to file meas#.txt

			// Unlink the SDRAM disk I/O driver
			FATFS_UnLinkDriver(SDRAMPath);

			char fname[30] = " ";

			sprintf(fname, "meas_%lu.txt", MeasNo);

			printf("Writing data to file %s... ", fname);

			// Link the SDRAM disk I/O driver
			if (FATFS_LinkDriver(&SDRAMDISK_Driver, SDRAMPath) != 0) {
				printf("	SDRAM FATFS link Error \r\n");
				_Error_Handler(__FILE__, __LINE__);
			}

			// Register the file system object to the FatFs module
			if (f_mount(&SDRAMFatFs, (TCHAR const*) SDRAMPath, 0) != FR_OK) {
				// FatFs Initialization Error
				printf("	SDRAM FATFS mount Error \r\n");
				_Error_Handler(__FILE__, __LINE__);
			}

			// Create and Open a new text file object with write access
			if (f_open(&MyFile, fname, FA_CREATE_ALWAYS | FA_WRITE)
					!= FR_OK) {
				// File Open for write Error
				printf("	SDRAM FATFS fopen Error \r\n");
				_Error_Handler(__FILE__, __LINE__);
			}

			char buffer[30];

			// Write data to the text file
			for (int idx = 0; idx < NoOfPoints; idx++) {
				sprintf(buffer, "%lu \r\n", ((uint32_t) Data.array[idx]));
				res = f_write(&MyFile, buffer, sizeof(buffer),
						(void *) &byteswritten);
			}

			if ((byteswritten == 0) || (res != FR_OK)) {
				printf("	SDRAM FATFS write Error \r\n");
				_Error_Handler(__FILE__, __LINE__);
			}

			// Close the text file
			f_close(&MyFile);
			// printf("SDRAM FATFS fclose Success \r\n");

			printf("Write OK \r\n");

			DirList();
		}

//			FATFS SDRAMFatFs;
//			FIL MyFile;
//			char SDRAMPath[4]; /* SDRAM card logical drive path */
//			uint8_t workBuffer[_MAX_SS];
//
//			const Diskio_drvTypeDef SDRAMDISK_Driver;
//
//			WriteData2FS(SDRAMDISK_Driver, SDRAMFatFs, &SDRAMPath[4], MyFile,
//					&Data, NoOfPoints, MeasNo);
//
//		}

		// setpoints: Adjust sampled points
		else if ((strcmp(Cmd, "setpoints") == 0) && (n > 0)) {
			// Allocate more or less data space
			NoOfPoints = (uint32_t) strtol(Arg, NULL, 10);
			printf("Old Data size is %u New NoOfPOints = %lu \r\n",
					Data.size, NoOfPoints);

			insertArray(&Data, NoOfPoints);
			printf("New Array size is %u \r\n", Data.size);
		}

		// setavg: Adjust average amount in samples
		else if ((strcmp(Cmd, "setavg") == 0) && (n > 0)) {
			AvgSize = (uint32_t) strtol(Arg, NULL, 10);
		}

		// setperiod: Adjust sample period in us
		else if ((strcmp(Cmd, "setperiod") == 0) && (n > 0)) {
			Period_us = (uint32_t) strtol(Arg, NULL, 10);
		}

		// setcount: Adjust countdown period in ms
		else if ((strcmp(Cmd, "setcount") == 0) && (n > 0)) {
			Count_ms = (uint32_t) strtol(Arg, NULL, 10);
		}

		// dir: Print file listing
		else if ((strcmp(Cmd, "dir") == 0) && (n == 0)) {

			// Unlink the SDRAM disk I/O driver
			FATFS_UnLinkDriver(SDRAMPath);

			// Link the SDRAM disk I/O driver
			if (FATFS_LinkDriver(&SDRAMDISK_Driver, SDRAMPath) != 0) {
				printf("	SDRAM FATFS link Error \r\n");
				_Error_Handler(__FILE__, __LINE__);
			}

			// Register the file system object to the FatFs module
			if (f_mount(&SDRAMFatFs, (TCHAR const*) SDRAMPath, 0) != FR_OK) {
				// FatFs Initialization Error
				printf("	SDRAM FATFS mount Error \r\n");
				_Error_Handler(__FILE__, __LINE__);
			}

			strcpy(buff, "");

			// File list
			res = scan_files(buff);

			// Disk free space
			DWORD fre_clust, fre_sect, tot_sect;
			FATFS *fsp;

			// Get volume information and free clusters of drive 1
			res = f_getfree(buff, &fre_clust, &fsp);
			if (res) {
				printf("Error: Filesystem free space check failed \r\n");
				_Error_Handler(__FILE__, __LINE__);
			}

			// Get total sectors and free sectors
			tot_sect = (fsp->n_fatent - 2) * fsp->csize;
			fre_sect = fre_clust * fsp->csize;

			// Print the free space (assuming 512 bytes/sector)
			printf(
					"%10lu KiB total drive space.\n%10lu KiB available (%s\%%). \n",
					(tot_sect / 2048), (fre_sect / 2048),
					myPrintf(
							((float) (fre_sect)) / ((float) (tot_sect))
									* 100.0));

		}

		// quit: Exit on next while
		else if ((strcmp(Cmd, "quit") == 0) && (n == 0)) {
			// Do nothing yet
		} else {
			printf("Wrong command or argument \r\n");
		}
	}

	// Free memory after quit
	freeArray(&Data);

	// Unlink the SDRAM disk I/O driver
	FATFS_UnLinkDriver(SDRAMPath);

	// Print informative messages
	InitScreen(LCD_COLOR_BLACK, LCD_COLOR_WHITE);
	LCDWrite(5, "Stop.");

	printf("Exit. Data freed. Stop. \r\n");

	/* USER CODE END 2 */

	/* Create the thread(s) */
	/* definition and creation of defaultTask */
	osThreadDef(defaultTask, StartDefaultTask, osPriorityNormal, 0, 128);
	defaultTaskHandle = osThreadCreate(osThread(defaultTask), NULL);

	/* Start scheduler */
	osKernelStart();

	/* We should never get here as control is now taken by the scheduler */

	/* Infinite loop */
	/* USER CODE BEGIN WHILE */
	while (1) {

	}

}

/* StartDefaultTask function */
void StartDefaultTask(void const * argument) {
	/* init code for FATFS */
	MX_FATFS_Init();

	/* init code for USB_HOST */
	MX_USB_HOST_Init();

	/* USER CODE BEGIN 5 */
	/* Infinite loop */
	for (;;) {
		osDelay(1);
		printf("Looping OS \r\n");

	}
}

/* USER CODE BEGIN 4 */

int __io_putchar(int ch) {
	uint8_t c[1];
	c[0] = ch & 0x00FF;
	HAL_UART_Transmit(&huart1, &*c, 1, 10);
	return ch;
}

int _write(int file, char *ptr, int len) {
	int DataIdx;
	for (DataIdx = 0; DataIdx < len; DataIdx++) {
		__io_putchar(*ptr++);
	}
	return len;
}

int __io_getchar(void) {
	HAL_StatusTypeDef Status = HAL_BUSY;
	uint8_t Data;

	while (Status != HAL_OK)
		Status = HAL_UART_Receive(&huart1, &Data, 1, 10);

	return (Data);
}

int _read(int file, char *ptr, int len) {
	int DataIdx;
	for (DataIdx = 0; DataIdx < len; DataIdx++) {
		*ptr++ = __io_getchar();
	}
	return len;
}

// FreeRTOS printf functions need this
void vOutputChar(const char cChar, const TickType_t xTicksToWait) {
	/* Eg. send a byte to the UART. */
}

BaseType_t xApplicationMemoryPermissions(uint32_t aAddress) {
	return 3;
}

// FreeRTOS heap4 calloc & realloc
void *pvPortCalloc(size_t nmemb, size_t size) {
	void *pvReturn;

	vTaskSuspendAll();
	{
		pvReturn = calloc(nmemb, size);
	}
	xTaskResumeAll();

	return pvReturn;
}

void *pvPortRealloc(void *pv, size_t size) {
	void *pvReturn;

	vTaskSuspendAll();
	{
		pvReturn = realloc(pv, size);
	}
	xTaskResumeAll();

	return pvReturn;
}

// FreeRTOS heap4 stuff (not needed)
// https://embeddedartistry.com/blog/2018/1/15/implementing-malloc-with-freertos

//void* malloc(size_t size) {
//	void* ptr = NULL;
//
//	if (size > 0) {
//		// We simply wrap the FreeRTOS call into a standard form
//		ptr = pvPortMalloc(size);
//	} // else NULL if there was an error
//
//	return ptr;
//}
//
//void free(void* ptr) {
//	if (ptr) {
//		// We simply wrap the FreeRTOS call into a standard form
//		vPortFree(ptr);
//	}
//}

/* USER CODE END 4 */

void _Error_Handler(char *file, int line) {
	/* USER CODE BEGIN Error_Handler_Debug */
	/* User can add his own implementation to report the HAL error return state */

	printf("\r\nError file = %s Line = %d \r\n", file, line);

	/* USER CODE END Error_Handler_Debug */
}

void SystemClock_Config(void)
{

  RCC_OscInitTypeDef RCC_OscInitStruct;
  RCC_ClkInitTypeDef RCC_ClkInitStruct;
  RCC_PeriphCLKInitTypeDef PeriphClkInitStruct;

    /**Configure the main internal regulator output voltage
    */
  __HAL_RCC_PWR_CLK_ENABLE();

  __HAL_PWR_VOLTAGESCALING_CONFIG(PWR_REGULATOR_VOLTAGE_SCALE1);

    /**Initializes the CPU, AHB and APB busses clocks
    */
  RCC_OscInitStruct.OscillatorType = RCC_OSCILLATORTYPE_HSE;
  RCC_OscInitStruct.HSEState = RCC_HSE_ON;
  RCC_OscInitStruct.PLL.PLLState = RCC_PLL_ON;
  RCC_OscInitStruct.PLL.PLLSource = RCC_PLLSOURCE_HSE;
  RCC_OscInitStruct.PLL.PLLM = 25;
  RCC_OscInitStruct.PLL.PLLN = 400;
  RCC_OscInitStruct.PLL.PLLP = RCC_PLLP_DIV2;
  RCC_OscInitStruct.PLL.PLLQ = 9;
  if (HAL_RCC_OscConfig(&RCC_OscInitStruct) != HAL_OK)
  {
    _Error_Handler(__FILE__, __LINE__);
  }

    /**Activate the Over-Drive mode
    */
  if (HAL_PWREx_EnableOverDrive() != HAL_OK)
  {
    _Error_Handler(__FILE__, __LINE__);
  }

    /**Initializes the CPU, AHB and APB busses clocks
    */
  RCC_ClkInitStruct.ClockType = RCC_CLOCKTYPE_HCLK|RCC_CLOCKTYPE_SYSCLK
                              |RCC_CLOCKTYPE_PCLK1|RCC_CLOCKTYPE_PCLK2;
  RCC_ClkInitStruct.SYSCLKSource = RCC_SYSCLKSOURCE_PLLCLK;
  RCC_ClkInitStruct.AHBCLKDivider = RCC_SYSCLK_DIV1;
  RCC_ClkInitStruct.APB1CLKDivider = RCC_HCLK_DIV4;
  RCC_ClkInitStruct.APB2CLKDivider = RCC_HCLK_DIV2;

  if (HAL_RCC_ClockConfig(&RCC_ClkInitStruct, FLASH_LATENCY_6) != HAL_OK)
  {
    _Error_Handler(__FILE__, __LINE__);
  }

  PeriphClkInitStruct.PeriphClockSelection = RCC_PERIPHCLK_LTDC|RCC_PERIPHCLK_USART1
                              |RCC_PERIPHCLK_I2C3;
  PeriphClkInitStruct.PLLSAI.PLLSAIN = 190;
  PeriphClkInitStruct.PLLSAI.PLLSAIR = 5;
  PeriphClkInitStruct.PLLSAI.PLLSAIQ = 2;
  PeriphClkInitStruct.PLLSAI.PLLSAIP = RCC_PLLSAIP_DIV2;
  PeriphClkInitStruct.PLLSAIDivQ = 1;
  PeriphClkInitStruct.PLLSAIDivR = RCC_PLLSAIDIVR_4;
  PeriphClkInitStruct.Usart1ClockSelection = RCC_USART1CLKSOURCE_PCLK2;
  PeriphClkInitStruct.I2c3ClockSelection = RCC_I2C3CLKSOURCE_PCLK1;
  if (HAL_RCCEx_PeriphCLKConfig(&PeriphClkInitStruct) != HAL_OK)
  {
    _Error_Handler(__FILE__, __LINE__);
  }

    /**Configure the Systick interrupt time
    */
  HAL_SYSTICK_Config(HAL_RCC_GetHCLKFreq()/1000);

    /**Configure the Systick
    */
  HAL_SYSTICK_CLKSourceConfig(SYSTICK_CLKSOURCE_HCLK);

  /* SysTick_IRQn interrupt configuration */
  HAL_NVIC_SetPriority(SysTick_IRQn, 15, 0);
}

/* ADC3 init function */
static void MX_ADC3_Init(void)
{

  ADC_ChannelConfTypeDef sConfig;

    /**Configure the global features of the ADC (Clock, Resolution, Data Alignment and number of conversion)
    */
  hadc3.Instance = ADC3;
  hadc3.Init.ClockPrescaler = ADC_CLOCK_SYNC_PCLK_DIV4;
  hadc3.Init.Resolution = ADC_RESOLUTION_12B;
  hadc3.Init.ScanConvMode = DISABLE;
  hadc3.Init.ContinuousConvMode = DISABLE;
  hadc3.Init.DiscontinuousConvMode = DISABLE;
  hadc3.Init.ExternalTrigConvEdge = ADC_EXTERNALTRIGCONVEDGE_RISING;
  hadc3.Init.ExternalTrigConv = ADC_EXTERNALTRIGCONV_T2_TRGO;
  hadc3.Init.DataAlign = ADC_DATAALIGN_RIGHT;
  hadc3.Init.NbrOfConversion = 1;
  hadc3.Init.DMAContinuousRequests = DISABLE;
  hadc3.Init.EOCSelection = ADC_EOC_SINGLE_CONV;
  if (HAL_ADC_Init(&hadc3) != HAL_OK)
  {
    _Error_Handler(__FILE__, __LINE__);
  }

    /**Configure for the selected ADC regular channel its corresponding rank in the sequencer and its sample time.
    */
  sConfig.Channel = ADC_CHANNEL_0;
  sConfig.Rank = ADC_REGULAR_RANK_1;
  sConfig.SamplingTime = ADC_SAMPLETIME_3CYCLES;
  if (HAL_ADC_ConfigChannel(&hadc3, &sConfig) != HAL_OK)
  {
    _Error_Handler(__FILE__, __LINE__);
  }

}

/* CRC init function */
static void MX_CRC_Init(void)
{

  hcrc.Instance = CRC;
  hcrc.Init.DefaultPolynomialUse = DEFAULT_POLYNOMIAL_ENABLE;
  hcrc.Init.DefaultInitValueUse = DEFAULT_INIT_VALUE_ENABLE;
  hcrc.Init.InputDataInversionMode = CRC_INPUTDATA_INVERSION_NONE;
  hcrc.Init.OutputDataInversionMode = CRC_OUTPUTDATA_INVERSION_DISABLE;
  hcrc.InputDataFormat = CRC_INPUTDATA_FORMAT_BYTES;
  if (HAL_CRC_Init(&hcrc) != HAL_OK)
  {
    _Error_Handler(__FILE__, __LINE__);
  }

}

/* DMA2D init function */
static void MX_DMA2D_Init(void)
{

  hdma2d.Instance = DMA2D;
  hdma2d.Init.Mode = DMA2D_M2M;
  hdma2d.Init.ColorMode = DMA2D_OUTPUT_ARGB8888;
  hdma2d.Init.OutputOffset = 0;
  hdma2d.LayerCfg[1].InputOffset = 0;
  hdma2d.LayerCfg[1].InputColorMode = DMA2D_INPUT_ARGB8888;
  hdma2d.LayerCfg[1].AlphaMode = DMA2D_NO_MODIF_ALPHA;
  hdma2d.LayerCfg[1].InputAlpha = 0;
  if (HAL_DMA2D_Init(&hdma2d) != HAL_OK)
  {
    _Error_Handler(__FILE__, __LINE__);
  }

  if (HAL_DMA2D_ConfigLayer(&hdma2d, 1) != HAL_OK)
  {
    _Error_Handler(__FILE__, __LINE__);
  }

}

/* I2C3 init function */
static void MX_I2C3_Init(void)
{

  hi2c3.Instance = I2C3;
  hi2c3.Init.Timing = 0x00C0EAFF;
  hi2c3.Init.OwnAddress1 = 224;
  hi2c3.Init.AddressingMode = I2C_ADDRESSINGMODE_7BIT;
  hi2c3.Init.DualAddressMode = I2C_DUALADDRESS_DISABLE;
  hi2c3.Init.OwnAddress2 = 0;
  hi2c3.Init.OwnAddress2Masks = I2C_OA2_NOMASK;
  hi2c3.Init.GeneralCallMode = I2C_GENERALCALL_DISABLE;
  hi2c3.Init.NoStretchMode = I2C_NOSTRETCH_DISABLE;
  if (HAL_I2C_Init(&hi2c3) != HAL_OK)
  {
    _Error_Handler(__FILE__, __LINE__);
  }

    /**Configure Analogue filter
    */
  if (HAL_I2CEx_ConfigAnalogFilter(&hi2c3, I2C_ANALOGFILTER_ENABLE) != HAL_OK)
  {
    _Error_Handler(__FILE__, __LINE__);
  }

    /**Configure Digital filter
    */
  if (HAL_I2CEx_ConfigDigitalFilter(&hi2c3, 0) != HAL_OK)
  {
    _Error_Handler(__FILE__, __LINE__);
  }

}

/* LTDC init function */
static void MX_LTDC_Init(void)
{

  LTDC_LayerCfgTypeDef pLayerCfg;

  hltdc.Instance = LTDC;
  hltdc.Init.HSPolarity = LTDC_HSPOLARITY_AL;
  hltdc.Init.VSPolarity = LTDC_VSPOLARITY_AL;
  hltdc.Init.DEPolarity = LTDC_DEPOLARITY_AL;
  hltdc.Init.PCPolarity = LTDC_PCPOLARITY_IPC;
  hltdc.Init.HorizontalSync = 40;
  hltdc.Init.VerticalSync = 9;
  hltdc.Init.AccumulatedHBP = 53;
  hltdc.Init.AccumulatedVBP = 11;
  hltdc.Init.AccumulatedActiveW = 533;
  hltdc.Init.AccumulatedActiveH = 283;
  hltdc.Init.TotalWidth = 565;
  hltdc.Init.TotalHeigh = 285;
  hltdc.Init.Backcolor.Blue = 0;
  hltdc.Init.Backcolor.Green = 0;
  hltdc.Init.Backcolor.Red = 0;
  if (HAL_LTDC_Init(&hltdc) != HAL_OK)
  {
    _Error_Handler(__FILE__, __LINE__);
  }

  pLayerCfg.WindowX0 = 0;
  pLayerCfg.WindowX1 = 480;
  pLayerCfg.WindowY0 = 0;
  pLayerCfg.WindowY1 = 272;
  pLayerCfg.PixelFormat = LTDC_PIXEL_FORMAT_ARGB8888;
  pLayerCfg.Alpha = 255;
  pLayerCfg.Alpha0 = 0;
  pLayerCfg.BlendingFactor1 = LTDC_BLENDING_FACTOR1_CA;
  pLayerCfg.BlendingFactor2 = LTDC_BLENDING_FACTOR2_CA;
  pLayerCfg.FBStartAdress = 0;
  pLayerCfg.ImageWidth = 0;
  pLayerCfg.ImageHeight = 0;
  pLayerCfg.Backcolor.Blue = 0;
  pLayerCfg.Backcolor.Green = 0;
  pLayerCfg.Backcolor.Red = 0;
  if (HAL_LTDC_ConfigLayer(&hltdc, &pLayerCfg, 0) != HAL_OK)
  {
    _Error_Handler(__FILE__, __LINE__);
  }

}

/* TIM2 init function */
static void MX_TIM2_Init(void)
{

  TIM_ClockConfigTypeDef sClockSourceConfig;
  TIM_MasterConfigTypeDef sMasterConfig;

  htim2.Instance = TIM2;
	htim2.Init.Prescaler = 99;
  htim2.Init.CounterMode = TIM_COUNTERMODE_UP;
	htim2.Init.Period = 0xFFFFFFFF;
  htim2.Init.ClockDivision = TIM_CLOCKDIVISION_DIV1;
  htim2.Init.AutoReloadPreload = TIM_AUTORELOAD_PRELOAD_DISABLE;
  if (HAL_TIM_Base_Init(&htim2) != HAL_OK)
  {
    _Error_Handler(__FILE__, __LINE__);
  }

  sClockSourceConfig.ClockSource = TIM_CLOCKSOURCE_INTERNAL;
  if (HAL_TIM_ConfigClockSource(&htim2, &sClockSourceConfig) != HAL_OK)
  {
    _Error_Handler(__FILE__, __LINE__);
  }

  sMasterConfig.MasterOutputTrigger = TIM_TRGO_UPDATE;
  sMasterConfig.MasterSlaveMode = TIM_MASTERSLAVEMODE_DISABLE;
  if (HAL_TIMEx_MasterConfigSynchronization(&htim2, &sMasterConfig) != HAL_OK)
  {
    _Error_Handler(__FILE__, __LINE__);
  }

}

/* TIM3 init function */
static void MX_TIM3_Init(void)
{

  TIM_ClockConfigTypeDef sClockSourceConfig;
  TIM_MasterConfigTypeDef sMasterConfig;

  htim3.Instance = TIM3;
  htim3.Init.Prescaler = 0;
  htim3.Init.CounterMode = TIM_COUNTERMODE_UP;
  htim3.Init.Period = 100;
  htim3.Init.ClockDivision = TIM_CLOCKDIVISION_DIV1;
  htim3.Init.AutoReloadPreload = TIM_AUTORELOAD_PRELOAD_DISABLE;
  if (HAL_TIM_Base_Init(&htim3) != HAL_OK)
  {
    _Error_Handler(__FILE__, __LINE__);
  }

  sClockSourceConfig.ClockSource = TIM_CLOCKSOURCE_INTERNAL;
  if (HAL_TIM_ConfigClockSource(&htim3, &sClockSourceConfig) != HAL_OK)
  {
    _Error_Handler(__FILE__, __LINE__);
  }

  sMasterConfig.MasterOutputTrigger = TIM_TRGO_UPDATE;
  sMasterConfig.MasterSlaveMode = TIM_MASTERSLAVEMODE_DISABLE;
  if (HAL_TIMEx_MasterConfigSynchronization(&htim3, &sMasterConfig) != HAL_OK)
  {
    _Error_Handler(__FILE__, __LINE__);
  }

}

/* USART1 init function */
static void MX_USART1_UART_Init(void)
{

  huart1.Instance = USART1;
  huart1.Init.BaudRate = 115200;
  huart1.Init.WordLength = UART_WORDLENGTH_8B;
  huart1.Init.StopBits = UART_STOPBITS_1;
  huart1.Init.Parity = UART_PARITY_NONE;
  huart1.Init.Mode = UART_MODE_TX_RX;
  huart1.Init.HwFlowCtl = UART_HWCONTROL_NONE;
  huart1.Init.OverSampling = UART_OVERSAMPLING_16;
  huart1.Init.OneBitSampling = UART_ONE_BIT_SAMPLE_DISABLE;
  huart1.AdvancedInit.AdvFeatureInit = UART_ADVFEATURE_NO_INIT;
  if (HAL_UART_Init(&huart1) != HAL_OK)
  {
    _Error_Handler(__FILE__, __LINE__);
  }

}

/* WWDG init function */
static void MX_WWDG_Init(void)
{

  hwwdg.Instance = WWDG;
  hwwdg.Init.Prescaler = WWDG_PRESCALER_8;
  hwwdg.Init.Window = 64;
  hwwdg.Init.Counter = 64;
  hwwdg.Init.EWIMode = WWDG_EWI_DISABLE;
//  if (HAL_WWDG_Init(&hwwdg) != HAL_OK)
//  {
//    _Error_Handler(__FILE__, __LINE__);
//  }

}

static void MX_DMA_Init(void)
{
  /* DMA controller clock enable */
  __HAL_RCC_DMA2_CLK_ENABLE();

  /* Configure DMA request hdma_memtomem_dma2_stream2 on DMA2_Stream2 */
  hdma_memtomem_dma2_stream2.Instance = DMA2_Stream2;
  hdma_memtomem_dma2_stream2.Init.Channel = DMA_CHANNEL_0;
  hdma_memtomem_dma2_stream2.Init.Direction = DMA_MEMORY_TO_MEMORY;
  hdma_memtomem_dma2_stream2.Init.PeriphInc = DMA_PINC_ENABLE;
  hdma_memtomem_dma2_stream2.Init.MemInc = DMA_MINC_ENABLE;
  hdma_memtomem_dma2_stream2.Init.PeriphDataAlignment = DMA_PDATAALIGN_BYTE;
  hdma_memtomem_dma2_stream2.Init.MemDataAlignment = DMA_MDATAALIGN_BYTE;
  hdma_memtomem_dma2_stream2.Init.Mode = DMA_NORMAL;
  hdma_memtomem_dma2_stream2.Init.Priority = DMA_PRIORITY_LOW;
  hdma_memtomem_dma2_stream2.Init.FIFOMode = DMA_FIFOMODE_ENABLE;
  hdma_memtomem_dma2_stream2.Init.FIFOThreshold = DMA_FIFO_THRESHOLD_FULL;
  hdma_memtomem_dma2_stream2.Init.MemBurst = DMA_MBURST_SINGLE;
  hdma_memtomem_dma2_stream2.Init.PeriphBurst = DMA_PBURST_SINGLE;
  if (HAL_DMA_Init(&hdma_memtomem_dma2_stream2) != HAL_OK)
  {
    _Error_Handler(__FILE__, __LINE__);
  }

  /* Configure DMA request hdma_memtomem_dma2_stream1 on DMA2_Stream1 */
  hdma_memtomem_dma2_stream1.Instance = DMA2_Stream1;
  hdma_memtomem_dma2_stream1.Init.Channel = DMA_CHANNEL_0;
  hdma_memtomem_dma2_stream1.Init.Direction = DMA_MEMORY_TO_MEMORY;
  hdma_memtomem_dma2_stream1.Init.PeriphInc = DMA_PINC_ENABLE;
  hdma_memtomem_dma2_stream1.Init.MemInc = DMA_MINC_ENABLE;
  hdma_memtomem_dma2_stream1.Init.PeriphDataAlignment = DMA_PDATAALIGN_BYTE;
  hdma_memtomem_dma2_stream1.Init.MemDataAlignment = DMA_MDATAALIGN_BYTE;
  hdma_memtomem_dma2_stream1.Init.Mode = DMA_NORMAL;
  hdma_memtomem_dma2_stream1.Init.Priority = DMA_PRIORITY_LOW;
  hdma_memtomem_dma2_stream1.Init.FIFOMode = DMA_FIFOMODE_ENABLE;
  hdma_memtomem_dma2_stream1.Init.FIFOThreshold = DMA_FIFO_THRESHOLD_FULL;
  hdma_memtomem_dma2_stream1.Init.MemBurst = DMA_MBURST_SINGLE;
  hdma_memtomem_dma2_stream1.Init.PeriphBurst = DMA_PBURST_SINGLE;
  if (HAL_DMA_Init(&hdma_memtomem_dma2_stream1) != HAL_OK)
  {
    _Error_Handler(__FILE__, __LINE__);
  }

  /* DMA interrupt init */
  /* DMA2_Stream0_IRQn interrupt configuration */
  HAL_NVIC_SetPriority(DMA2_Stream0_IRQn, 5, 0);
  HAL_NVIC_EnableIRQ(DMA2_Stream0_IRQn);

}
/* FMC initialization function */
static void MX_FMC_Init(void)
{
  FMC_SDRAM_TimingTypeDef SdramTiming;

  /** Perform the SDRAM1 memory initialization sequence
  */
  hsdram1.Instance = FMC_SDRAM_DEVICE;
  /* hsdram1.Init */
  hsdram1.Init.SDBank = FMC_SDRAM_BANK1;
  hsdram1.Init.ColumnBitsNumber = FMC_SDRAM_COLUMN_BITS_NUM_8;
  hsdram1.Init.RowBitsNumber = FMC_SDRAM_ROW_BITS_NUM_12;
  hsdram1.Init.MemoryDataWidth = FMC_SDRAM_MEM_BUS_WIDTH_16;
  hsdram1.Init.InternalBankNumber = FMC_SDRAM_INTERN_BANKS_NUM_4;
  hsdram1.Init.CASLatency = FMC_SDRAM_CAS_LATENCY_2;
  hsdram1.Init.WriteProtection = FMC_SDRAM_WRITE_PROTECTION_DISABLE;
  hsdram1.Init.SDClockPeriod = FMC_SDRAM_CLOCK_PERIOD_2;
  hsdram1.Init.ReadBurst = FMC_SDRAM_RBURST_ENABLE;
  hsdram1.Init.ReadPipeDelay = FMC_SDRAM_RPIPE_DELAY_0;
  /* SdramTiming */
  SdramTiming.LoadToActiveDelay = 2;
  SdramTiming.ExitSelfRefreshDelay = 7;
  SdramTiming.SelfRefreshTime = 4;
  SdramTiming.RowCycleDelay = 6;
  SdramTiming.WriteRecoveryTime = 2;
  SdramTiming.RPDelay = 2;
  SdramTiming.RCDDelay = 2;

  if (HAL_SDRAM_Init(&hsdram1, &SdramTiming) != HAL_OK)
  {
    _Error_Handler(__FILE__, __LINE__);
  }

}

/** Configure pins as
        * Analog
        * Input
        * Output
        * EVENT_OUT
        * EXTI
     PE2   ------> QUADSPI_BK1_IO2
     PG14   ------> ETH_TXD1
     PB8   ------> I2C1_SCL
     PD7   ------> SPDIFRX_IN0
     PC12   ------> SDMMC1_CK
     PE5   ------> DCMI_D6
     PE6   ------> DCMI_D7
     PG13   ------> ETH_TXD0
     PB9   ------> I2C1_SDA
     PB6   ------> QUADSPI_BK1_NCS
     PG11   ------> ETH_TX_EN
     PC11   ------> SDMMC1_D3
     PC10   ------> SDMMC1_D2
     PA12   ------> USB_OTG_FS_DP
     PI4   ------> SAI2_MCLK_A
     PG10   ------> SAI2_SD_B
     PD3   ------> DCMI_D5
     PA11   ------> USB_OTG_FS_DM
     PI5   ------> SAI2_SCK_A
     PI7   ------> SAI2_FS_A
     PI6   ------> SAI2_SD_A
     PG9   ------> DCMI_VSYNC
     PD2   ------> SDMMC1_CMD
     PI1   ------> SPI2_SCK
     PA10   ------> USB_OTG_FS_ID
     PH14   ------> DCMI_D4
     PI0   ------> S_TIM5_CH4
     PC9   ------> SDMMC1_D1
     PA8   ------> S_TIM1_CH1
     PC8   ------> SDMMC1_D0
     PC7   ------> USART6_RX
     PC6   ------> USART6_TX
     PC1   ------> ETH_MDC
     PB2   ------> QUADSPI_CLK
     PD12   ------> QUADSPI_BK1_IO1
     PD13   ------> QUADSPI_BK1_IO3
     PH12   ------> DCMI_D3
     PA1   ------> ETH_REF_CLK
     PA4   ------> DCMI_HSYNC
     PC4   ------> ETH_RXD0
     PD11   ------> QUADSPI_BK1_IO0
     PH9   ------> DCMI_D0
     PH11   ------> DCMI_D2
     PA2   ------> ETH_MDIO
     PA6   ------> DCMI_PIXCLK
     PC5   ------> ETH_RXD1
     PH6   ------> S_TIM12_CH1
     PH10   ------> DCMI_D1
     PA7   ------> ETH_CRS_DV
     PB14   ------> SPI2_MISO
     PB15   ------> SPI2_MOSI
*/
static void MX_GPIO_Init(void)
{

  GPIO_InitTypeDef GPIO_InitStruct;

  /* GPIO Ports Clock Enable */
  __HAL_RCC_GPIOE_CLK_ENABLE();
  __HAL_RCC_GPIOG_CLK_ENABLE();
  __HAL_RCC_GPIOB_CLK_ENABLE();
  __HAL_RCC_GPIOD_CLK_ENABLE();
  __HAL_RCC_GPIOC_CLK_ENABLE();
  __HAL_RCC_GPIOA_CLK_ENABLE();
  __HAL_RCC_GPIOJ_CLK_ENABLE();
  __HAL_RCC_GPIOI_CLK_ENABLE();
  __HAL_RCC_GPIOK_CLK_ENABLE();
  __HAL_RCC_GPIOF_CLK_ENABLE();
  __HAL_RCC_GPIOH_CLK_ENABLE();

  /*Configure GPIO pin Output Level */
  HAL_GPIO_WritePin(OTG_FS_PowerSwitchOn_GPIO_Port, OTG_FS_PowerSwitchOn_Pin, GPIO_PIN_SET);

  /*Configure GPIO pin Output Level */
  HAL_GPIO_WritePin(GPIOI, ARDUINO_D7_Pin|ARDUINO_D8_Pin|LCD_DISP_Pin, GPIO_PIN_RESET);

  /*Configure GPIO pin Output Level */
  HAL_GPIO_WritePin(LCD_BL_CTRL_GPIO_Port, LCD_BL_CTRL_Pin, GPIO_PIN_RESET);

  /*Configure GPIO pin Output Level */
  HAL_GPIO_WritePin(DCMI_PWR_EN_GPIO_Port, DCMI_PWR_EN_Pin, GPIO_PIN_RESET);

  /*Configure GPIO pin Output Level */
  HAL_GPIO_WritePin(GPIOG, ARDUINO_D4_Pin|ARDUINO_D2_Pin|EXT_RST_Pin, GPIO_PIN_RESET);

  /*Configure GPIO pin : OTG_HS_OverCurrent_Pin */
  GPIO_InitStruct.Pin = OTG_HS_OverCurrent_Pin;
  GPIO_InitStruct.Mode = GPIO_MODE_INPUT;
  GPIO_InitStruct.Pull = GPIO_NOPULL;
  HAL_GPIO_Init(OTG_HS_OverCurrent_GPIO_Port, &GPIO_InitStruct);

  /*Configure GPIO pin : QSPI_D2_Pin */
  GPIO_InitStruct.Pin = QSPI_D2_Pin;
  GPIO_InitStruct.Mode = GPIO_MODE_AF_PP;
  GPIO_InitStruct.Pull = GPIO_NOPULL;
  GPIO_InitStruct.Speed = GPIO_SPEED_FREQ_VERY_HIGH;
  GPIO_InitStruct.Alternate = GPIO_AF9_QUADSPI;
  HAL_GPIO_Init(QSPI_D2_GPIO_Port, &GPIO_InitStruct);

  /*Configure GPIO pins : RMII_TXD1_Pin RMII_TXD0_Pin RMII_TX_EN_Pin */
  GPIO_InitStruct.Pin = RMII_TXD1_Pin|RMII_TXD0_Pin|RMII_TX_EN_Pin;
  GPIO_InitStruct.Mode = GPIO_MODE_AF_PP;
  GPIO_InitStruct.Pull = GPIO_NOPULL;
  GPIO_InitStruct.Speed = GPIO_SPEED_FREQ_VERY_HIGH;
  GPIO_InitStruct.Alternate = GPIO_AF11_ETH;
  HAL_GPIO_Init(GPIOG, &GPIO_InitStruct);

  /*Configure GPIO pins : ARDUINO_SCL_D15_Pin ARDUINO_SDA_D14_Pin */
  GPIO_InitStruct.Pin = ARDUINO_SCL_D15_Pin|ARDUINO_SDA_D14_Pin;
  GPIO_InitStruct.Mode = GPIO_MODE_AF_OD;
  GPIO_InitStruct.Pull = GPIO_PULLUP;
  GPIO_InitStruct.Speed = GPIO_SPEED_FREQ_LOW;
  GPIO_InitStruct.Alternate = GPIO_AF4_I2C1;
  HAL_GPIO_Init(GPIOB, &GPIO_InitStruct);

  /*Configure GPIO pin : SPDIF_RX0_Pin */
  GPIO_InitStruct.Pin = SPDIF_RX0_Pin;
  GPIO_InitStruct.Mode = GPIO_MODE_AF_PP;
  GPIO_InitStruct.Pull = GPIO_NOPULL;
  GPIO_InitStruct.Speed = GPIO_SPEED_FREQ_LOW;
  GPIO_InitStruct.Alternate = GPIO_AF8_SPDIFRX;
  HAL_GPIO_Init(SPDIF_RX0_GPIO_Port, &GPIO_InitStruct);

  /*Configure GPIO pins : SDMMC_CK_Pin SDMMC_D3_Pin SDMMC_D2_Pin PC9
                           PC8 */
  GPIO_InitStruct.Pin = SDMMC_CK_Pin|SDMMC_D3_Pin|SDMMC_D2_Pin|GPIO_PIN_9
                          |GPIO_PIN_8;
  GPIO_InitStruct.Mode = GPIO_MODE_AF_PP;
  GPIO_InitStruct.Pull = GPIO_NOPULL;
  GPIO_InitStruct.Speed = GPIO_SPEED_FREQ_VERY_HIGH;
  GPIO_InitStruct.Alternate = GPIO_AF12_SDMMC1;
  HAL_GPIO_Init(GPIOC, &GPIO_InitStruct);

  /*Configure GPIO pins : DCMI_D6_Pin DCMI_D7_Pin */
  GPIO_InitStruct.Pin = DCMI_D6_Pin|DCMI_D7_Pin;
  GPIO_InitStruct.Mode = GPIO_MODE_AF_PP;
  GPIO_InitStruct.Pull = GPIO_NOPULL;
  GPIO_InitStruct.Speed = GPIO_SPEED_FREQ_LOW;
  GPIO_InitStruct.Alternate = GPIO_AF13_DCMI;
  HAL_GPIO_Init(GPIOE, &GPIO_InitStruct);

  /*Configure GPIO pin : QSPI_NCS_Pin */
  GPIO_InitStruct.Pin = QSPI_NCS_Pin;
  GPIO_InitStruct.Mode = GPIO_MODE_AF_PP;
  GPIO_InitStruct.Pull = GPIO_NOPULL;
  GPIO_InitStruct.Speed = GPIO_SPEED_FREQ_VERY_HIGH;
  GPIO_InitStruct.Alternate = GPIO_AF10_QUADSPI;
  HAL_GPIO_Init(QSPI_NCS_GPIO_Port, &GPIO_InitStruct);

  /*Configure GPIO pin : OTG_FS_VBUS_Pin */
  GPIO_InitStruct.Pin = OTG_FS_VBUS_Pin;
  GPIO_InitStruct.Mode = GPIO_MODE_INPUT;
  GPIO_InitStruct.Pull = GPIO_NOPULL;
  HAL_GPIO_Init(OTG_FS_VBUS_GPIO_Port, &GPIO_InitStruct);

  /*Configure GPIO pin : Audio_INT_Pin */
  GPIO_InitStruct.Pin = Audio_INT_Pin;
  GPIO_InitStruct.Mode = GPIO_MODE_EVT_RISING;
  GPIO_InitStruct.Pull = GPIO_NOPULL;
  HAL_GPIO_Init(Audio_INT_GPIO_Port, &GPIO_InitStruct);

  /*Configure GPIO pins : OTG_FS_P_Pin OTG_FS_N_Pin OTG_FS_ID_Pin */
  GPIO_InitStruct.Pin = OTG_FS_P_Pin|OTG_FS_N_Pin|OTG_FS_ID_Pin;
  GPIO_InitStruct.Mode = GPIO_MODE_AF_PP;
  GPIO_InitStruct.Pull = GPIO_NOPULL;
  GPIO_InitStruct.Speed = GPIO_SPEED_FREQ_VERY_HIGH;
  GPIO_InitStruct.Alternate = GPIO_AF10_OTG_FS;
  HAL_GPIO_Init(GPIOA, &GPIO_InitStruct);

  /*Configure GPIO pins : SAI2_MCLKA_Pin SAI2_SCKA_Pin SAI2_FSA_Pin SAI2_SDA_Pin */
  GPIO_InitStruct.Pin = SAI2_MCLKA_Pin|SAI2_SCKA_Pin|SAI2_FSA_Pin|SAI2_SDA_Pin;
  GPIO_InitStruct.Mode = GPIO_MODE_AF_PP;
  GPIO_InitStruct.Pull = GPIO_NOPULL;
  GPIO_InitStruct.Speed = GPIO_SPEED_FREQ_LOW;
  GPIO_InitStruct.Alternate = GPIO_AF10_SAI2;
  HAL_GPIO_Init(GPIOI, &GPIO_InitStruct);

  /*Configure GPIO pin : SAI2_SDB_Pin */
  GPIO_InitStruct.Pin = SAI2_SDB_Pin;
  GPIO_InitStruct.Mode = GPIO_MODE_AF_PP;
  GPIO_InitStruct.Pull = GPIO_NOPULL;
  GPIO_InitStruct.Speed = GPIO_SPEED_FREQ_LOW;
  GPIO_InitStruct.Alternate = GPIO_AF10_SAI2;
  HAL_GPIO_Init(SAI2_SDB_GPIO_Port, &GPIO_InitStruct);

  /*Configure GPIO pin : OTG_FS_PowerSwitchOn_Pin */
  GPIO_InitStruct.Pin = OTG_FS_PowerSwitchOn_Pin;
  GPIO_InitStruct.Mode = GPIO_MODE_OUTPUT_PP;
  GPIO_InitStruct.Pull = GPIO_NOPULL;
  GPIO_InitStruct.Speed = GPIO_SPEED_FREQ_LOW;
  HAL_GPIO_Init(OTG_FS_PowerSwitchOn_GPIO_Port, &GPIO_InitStruct);

  /*Configure GPIO pin : DCMI_D5_Pin */
  GPIO_InitStruct.Pin = DCMI_D5_Pin;
  GPIO_InitStruct.Mode = GPIO_MODE_AF_PP;
  GPIO_InitStruct.Pull = GPIO_NOPULL;
  GPIO_InitStruct.Speed = GPIO_SPEED_FREQ_LOW;
  GPIO_InitStruct.Alternate = GPIO_AF13_DCMI;
  HAL_GPIO_Init(DCMI_D5_GPIO_Port, &GPIO_InitStruct);

  /*Configure GPIO pins : ARDUINO_D7_Pin ARDUINO_D8_Pin LCD_DISP_Pin */
  GPIO_InitStruct.Pin = ARDUINO_D7_Pin|ARDUINO_D8_Pin|LCD_DISP_Pin;
  GPIO_InitStruct.Mode = GPIO_MODE_OUTPUT_PP;
  GPIO_InitStruct.Pull = GPIO_NOPULL;
  GPIO_InitStruct.Speed = GPIO_SPEED_FREQ_LOW;
  HAL_GPIO_Init(GPIOI, &GPIO_InitStruct);

  /*Configure GPIO pin : uSD_Detect_Pin */
  GPIO_InitStruct.Pin = uSD_Detect_Pin;
  GPIO_InitStruct.Mode = GPIO_MODE_INPUT;
  GPIO_InitStruct.Pull = GPIO_NOPULL;
  HAL_GPIO_Init(uSD_Detect_GPIO_Port, &GPIO_InitStruct);

  /*Configure GPIO pin : LCD_BL_CTRL_Pin */
  GPIO_InitStruct.Pin = LCD_BL_CTRL_Pin;
  GPIO_InitStruct.Mode = GPIO_MODE_OUTPUT_PP;
  GPIO_InitStruct.Pull = GPIO_NOPULL;
  GPIO_InitStruct.Speed = GPIO_SPEED_FREQ_LOW;
  HAL_GPIO_Init(LCD_BL_CTRL_GPIO_Port, &GPIO_InitStruct);

  /*Configure GPIO pin : DCMI_VSYNC_Pin */
  GPIO_InitStruct.Pin = DCMI_VSYNC_Pin;
  GPIO_InitStruct.Mode = GPIO_MODE_AF_PP;
  GPIO_InitStruct.Pull = GPIO_NOPULL;
  GPIO_InitStruct.Speed = GPIO_SPEED_FREQ_LOW;
  GPIO_InitStruct.Alternate = GPIO_AF13_DCMI;
  HAL_GPIO_Init(DCMI_VSYNC_GPIO_Port, &GPIO_InitStruct);

  /*Configure GPIO pin : OTG_FS_OverCurrent_Pin */
  GPIO_InitStruct.Pin = OTG_FS_OverCurrent_Pin;
  GPIO_InitStruct.Mode = GPIO_MODE_INPUT;
  GPIO_InitStruct.Pull = GPIO_NOPULL;
  HAL_GPIO_Init(OTG_FS_OverCurrent_GPIO_Port, &GPIO_InitStruct);

  /*Configure GPIO pin : SDMMC_D0_Pin */
  GPIO_InitStruct.Pin = SDMMC_D0_Pin;
  GPIO_InitStruct.Mode = GPIO_MODE_AF_PP;
  GPIO_InitStruct.Pull = GPIO_NOPULL;
  GPIO_InitStruct.Speed = GPIO_SPEED_FREQ_VERY_HIGH;
  GPIO_InitStruct.Alternate = GPIO_AF12_SDMMC1;
  HAL_GPIO_Init(SDMMC_D0_GPIO_Port, &GPIO_InitStruct);

  /*Configure GPIO pins : TP3_Pin NC2_Pin */
  GPIO_InitStruct.Pin = TP3_Pin|NC2_Pin;
  GPIO_InitStruct.Mode = GPIO_MODE_INPUT;
  GPIO_InitStruct.Pull = GPIO_NOPULL;
  HAL_GPIO_Init(GPIOH, &GPIO_InitStruct);

  /*Configure GPIO pin : ARDUINO_SCK_D13_Pin */
  GPIO_InitStruct.Pin = ARDUINO_SCK_D13_Pin;
  GPIO_InitStruct.Mode = GPIO_MODE_AF_PP;
  GPIO_InitStruct.Pull = GPIO_NOPULL;
  GPIO_InitStruct.Speed = GPIO_SPEED_FREQ_LOW;
  GPIO_InitStruct.Alternate = GPIO_AF5_SPI2;
  HAL_GPIO_Init(ARDUINO_SCK_D13_GPIO_Port, &GPIO_InitStruct);

  /*Configure GPIO pin : DCMI_PWR_EN_Pin */
  GPIO_InitStruct.Pin = DCMI_PWR_EN_Pin;
  GPIO_InitStruct.Mode = GPIO_MODE_OUTPUT_PP;
  GPIO_InitStruct.Pull = GPIO_NOPULL;
  GPIO_InitStruct.Speed = GPIO_SPEED_FREQ_LOW;
  HAL_GPIO_Init(DCMI_PWR_EN_GPIO_Port, &GPIO_InitStruct);

  /*Configure GPIO pins : DCMI_D4_Pin DCMI_D3_Pin DCMI_D0_Pin DCMI_D2_Pin
                           DCMI_D1_Pin */
  GPIO_InitStruct.Pin = DCMI_D4_Pin|DCMI_D3_Pin|DCMI_D0_Pin|DCMI_D2_Pin
                          |DCMI_D1_Pin;
  GPIO_InitStruct.Mode = GPIO_MODE_AF_PP;
  GPIO_InitStruct.Pull = GPIO_NOPULL;
  GPIO_InitStruct.Speed = GPIO_SPEED_FREQ_LOW;
  GPIO_InitStruct.Alternate = GPIO_AF13_DCMI;
  HAL_GPIO_Init(GPIOH, &GPIO_InitStruct);

  /*Configure GPIO pin : ARDUINO_PWM_CS_D10_Pin */
  GPIO_InitStruct.Pin = ARDUINO_PWM_CS_D10_Pin;
  GPIO_InitStruct.Mode = GPIO_MODE_AF_PP;
  GPIO_InitStruct.Pull = GPIO_NOPULL;
  GPIO_InitStruct.Speed = GPIO_SPEED_FREQ_LOW;
  GPIO_InitStruct.Alternate = GPIO_AF2_TIM5;
  HAL_GPIO_Init(ARDUINO_PWM_CS_D10_GPIO_Port, &GPIO_InitStruct);

  /*Configure GPIO pin : ARDUINO_PWM_D5_Pin */
  GPIO_InitStruct.Pin = ARDUINO_PWM_D5_Pin;
  GPIO_InitStruct.Mode = GPIO_MODE_AF_PP;
  GPIO_InitStruct.Pull = GPIO_NOPULL;
  GPIO_InitStruct.Speed = GPIO_SPEED_FREQ_LOW;
  GPIO_InitStruct.Alternate = GPIO_AF1_TIM1;
  HAL_GPIO_Init(ARDUINO_PWM_D5_GPIO_Port, &GPIO_InitStruct);

  /*Configure GPIO pin : LCD_INT_Pin */
  GPIO_InitStruct.Pin = LCD_INT_Pin;
  GPIO_InitStruct.Mode = GPIO_MODE_EVT_RISING;
  GPIO_InitStruct.Pull = GPIO_NOPULL;
  HAL_GPIO_Init(LCD_INT_GPIO_Port, &GPIO_InitStruct);

  /*Configure GPIO pins : ARDUINO_RX_D0_Pin ARDUINO_TX_D1_Pin */
  GPIO_InitStruct.Pin = ARDUINO_RX_D0_Pin|ARDUINO_TX_D1_Pin;
  GPIO_InitStruct.Mode = GPIO_MODE_AF_PP;
  GPIO_InitStruct.Pull = GPIO_NOPULL;
  GPIO_InitStruct.Speed = GPIO_SPEED_FREQ_VERY_HIGH;
  GPIO_InitStruct.Alternate = GPIO_AF8_USART6;
  HAL_GPIO_Init(GPIOC, &GPIO_InitStruct);

  /*Configure GPIO pins : ARDUINO_D4_Pin ARDUINO_D2_Pin EXT_RST_Pin */
  GPIO_InitStruct.Pin = ARDUINO_D4_Pin|ARDUINO_D2_Pin|EXT_RST_Pin;
  GPIO_InitStruct.Mode = GPIO_MODE_OUTPUT_PP;
  GPIO_InitStruct.Pull = GPIO_NOPULL;
  GPIO_InitStruct.Speed = GPIO_SPEED_FREQ_LOW;
  HAL_GPIO_Init(GPIOG, &GPIO_InitStruct);

  /*Configure GPIO pins : RMII_MDC_Pin RMII_RXD0_Pin RMII_RXD1_Pin */
  GPIO_InitStruct.Pin = RMII_MDC_Pin|RMII_RXD0_Pin|RMII_RXD1_Pin;
  GPIO_InitStruct.Mode = GPIO_MODE_AF_PP;
  GPIO_InitStruct.Pull = GPIO_NOPULL;
  GPIO_InitStruct.Speed = GPIO_SPEED_FREQ_VERY_HIGH;
  GPIO_InitStruct.Alternate = GPIO_AF11_ETH;
  HAL_GPIO_Init(GPIOC, &GPIO_InitStruct);

  /*Configure GPIO pin : PB2 */
  GPIO_InitStruct.Pin = GPIO_PIN_2;
  GPIO_InitStruct.Mode = GPIO_MODE_AF_PP;
  GPIO_InitStruct.Pull = GPIO_NOPULL;
  GPIO_InitStruct.Speed = GPIO_SPEED_FREQ_VERY_HIGH;
  GPIO_InitStruct.Alternate = GPIO_AF9_QUADSPI;
  HAL_GPIO_Init(GPIOB, &GPIO_InitStruct);

  /*Configure GPIO pins : QSPI_D1_Pin QSPI_D3_Pin QSPI_D0_Pin */
  GPIO_InitStruct.Pin = QSPI_D1_Pin|QSPI_D3_Pin|QSPI_D0_Pin;
  GPIO_InitStruct.Mode = GPIO_MODE_AF_PP;
  GPIO_InitStruct.Pull = GPIO_NOPULL;
  GPIO_InitStruct.Speed = GPIO_SPEED_FREQ_VERY_HIGH;
  GPIO_InitStruct.Alternate = GPIO_AF9_QUADSPI;
  HAL_GPIO_Init(GPIOD, &GPIO_InitStruct);

  /*Configure GPIO pin : RMII_RXER_Pin */
  GPIO_InitStruct.Pin = RMII_RXER_Pin;
  GPIO_InitStruct.Mode = GPIO_MODE_INPUT;
  GPIO_InitStruct.Pull = GPIO_NOPULL;
  HAL_GPIO_Init(RMII_RXER_GPIO_Port, &GPIO_InitStruct);

  /*Configure GPIO pins : RMII_REF_CLK_Pin RMII_MDIO_Pin RMII_CRS_DV_Pin */
  GPIO_InitStruct.Pin = RMII_REF_CLK_Pin|RMII_MDIO_Pin|RMII_CRS_DV_Pin;
  GPIO_InitStruct.Mode = GPIO_MODE_AF_PP;
  GPIO_InitStruct.Pull = GPIO_NOPULL;
  GPIO_InitStruct.Speed = GPIO_SPEED_FREQ_VERY_HIGH;
  GPIO_InitStruct.Alternate = GPIO_AF11_ETH;
  HAL_GPIO_Init(GPIOA, &GPIO_InitStruct);

  /*Configure GPIO pins : DCMI_HSYNC_Pin PA6 */
  GPIO_InitStruct.Pin = DCMI_HSYNC_Pin|GPIO_PIN_6;
  GPIO_InitStruct.Mode = GPIO_MODE_AF_PP;
  GPIO_InitStruct.Pull = GPIO_NOPULL;
  GPIO_InitStruct.Speed = GPIO_SPEED_FREQ_LOW;
  GPIO_InitStruct.Alternate = GPIO_AF13_DCMI;
  HAL_GPIO_Init(GPIOA, &GPIO_InitStruct);

  /*Configure GPIO pin : ARDUINO_PWM_D6_Pin */
  GPIO_InitStruct.Pin = ARDUINO_PWM_D6_Pin;
  GPIO_InitStruct.Mode = GPIO_MODE_AF_PP;
  GPIO_InitStruct.Pull = GPIO_NOPULL;
  GPIO_InitStruct.Speed = GPIO_SPEED_FREQ_LOW;
  GPIO_InitStruct.Alternate = GPIO_AF9_TIM12;
  HAL_GPIO_Init(ARDUINO_PWM_D6_GPIO_Port, &GPIO_InitStruct);

  /*Configure GPIO pins : ARDUINO_MISO_D12_Pin ARDUINO_MOSI_PWM_D11_Pin */
  GPIO_InitStruct.Pin = ARDUINO_MISO_D12_Pin|ARDUINO_MOSI_PWM_D11_Pin;
  GPIO_InitStruct.Mode = GPIO_MODE_AF_PP;
  GPIO_InitStruct.Pull = GPIO_NOPULL;
  GPIO_InitStruct.Speed = GPIO_SPEED_FREQ_LOW;
  GPIO_InitStruct.Alternate = GPIO_AF5_SPI2;
  HAL_GPIO_Init(GPIOB, &GPIO_InitStruct);

}

void HAL_TIM_PeriodElapsedCallback(TIM_HandleTypeDef *htim)
{
  if (htim->Instance == TIM1) {
    HAL_IncTick();
  }
}

/************************ (C) COPYRIGHT STMicroelectronics *****END OF FILE****/
